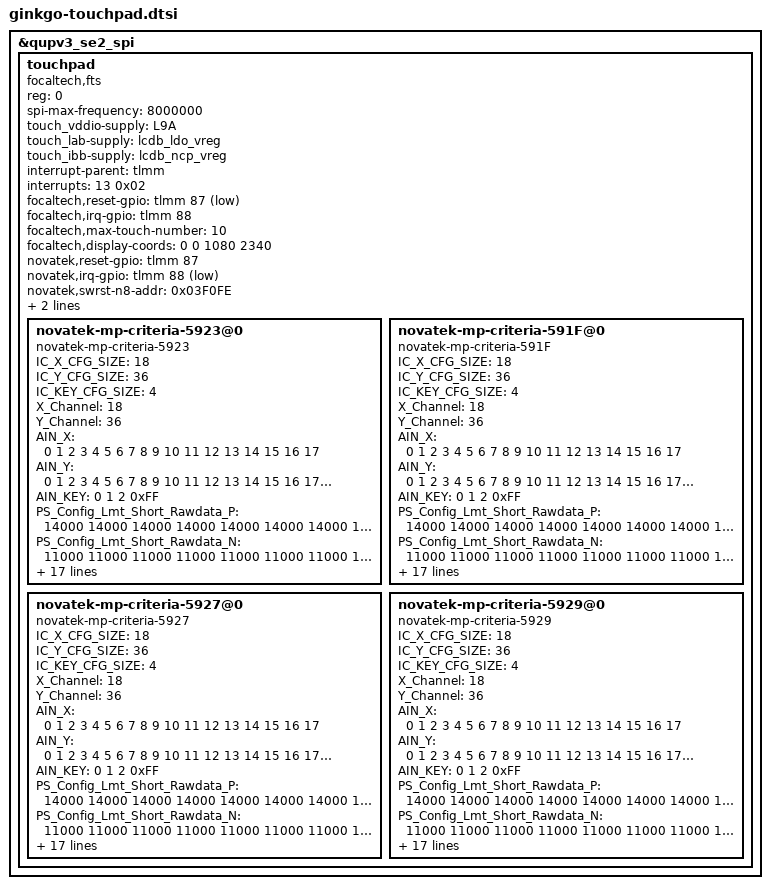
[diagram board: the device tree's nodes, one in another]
/*
 * TouchPad Device Tree For Xiaomi C3J
 */

&qupv3_se2_spi {

	status = "ok";

	touchpad{
		status = "ok";
		compatible = "focaltech,fts","novatek,NVT-ts-spi";
		reg = <0>; //Same as CS ID

		/* SPI Configuration */
		//spi-cs-high;
		spi-max-frequency = <8000000>;	//4800000,5000000,8000000,9600000,15000000,19200000

		/* regulator Configuration */
		touch_vddio-supply = <&L9A>;
		touch_lab-supply = <&lcdb_ldo_vreg>;
		touch_ibb-supply = <&lcdb_ncp_vreg>;

		/*
		 * [IC Vendor]Focaltech [IC Name]FT8719 - device tree
		 ********************************************************************
		 */

		/* Focaltech GPIO Configuration */
		interrupt-parent = <&tlmm>;
		interrupts = <13 0x02>;
		focaltech,reset-gpio = <&tlmm 87 0x01>;
		focaltech,irq-gpio = <&tlmm 88 0x02>;
		focaltech,max-touch-number = <10>;
		focaltech,display-coords =  <0 0 1080 2340>;

		/* Pinctrl Configuration */
		//pinctrl-names = "pmx_ts_active","pmx_ts_suspend","pmx_ts_release";
		//pinctrl-0 = <&ts_int_active &ts_reset_active>;
		//pinctrl-1 = <&ts_int_suspend &ts_reset_suspend>;
		//pinctrl-2 = <&ts_release>;

		/* Touch Key Configuration */
		//focaltech,have-key;
		//focaltech,key-number = <3>;
		//focaltech,keys = <139 102 158>;
		//focaltech,key-x-coords = <200 600 800>;
		//focaltech,key-y-coords = <2000 2000 2000>;

		/*
		 * [IC Vendor]Novatek [IC Name]NT36672A - device tree
		 ********************************************************************
		 */

		/* Novatek GPIO Configuration */
		novatek,reset-gpio = <&tlmm 87 0x00>;
		novatek,irq-gpio = <&tlmm 88 0x2001>;

		/* 525 */
		//novatek,swrst-n8-addr = <0x01F01A>;

		/* 672A, 525B */
		novatek,swrst-n8-addr = <0x03F0FE>;
		novatek,spi-rd-fast-addr = <0x03F310>;

		/* MP */
		novatek,mp-support-dt;

		/* for Xiaomi C3J 672A EBBG 6.3" */
		novatek-mp-criteria-5923@0 {/*{{{*/
			#address-cells = <1>;
			#size-cells = <0>;
			compatible = "novatek-mp-criteria-5923";

			/* MP Config */
			IC_X_CFG_SIZE = <18>;
			IC_Y_CFG_SIZE = <36>;
			IC_KEY_CFG_SIZE = <4>;
			X_Channel = <18>;
			Y_Channel = <36>;
			AIN_X = <0 1 2 3 4 5 6 7 8 9 10 11 12 13 14 15 16 17>;
			AIN_Y = <0 1 2 3 4 5 6 7 8 9 10 11 12 13 14 15 16 17
						18 19 20 21 22 23 24 25 26 27 28 29 30 31 32 33 34 35>;
			AIN_KEY = <0 1 2 0xFF>;

			/* MP Criteria */
			PS_Config_Lmt_Short_Rawdata_P = <
				14000 14000 14000 14000 14000 14000 14000 14000 14000 14000 14000 14000 14000 14000 14000 14000 14000 14000  
				14000 14000 14000 14000 14000 14000 14000 14000 14000 14000 14000 14000 14000 14000 14000 14000 14000 14000
				14000 14000 14000 14000 14000 14000 14000 14000 14000 14000 14000 14000 14000 14000 14000 14000 14000 14000
				14000 14000 14000 14000 14000 14000 14000 14000 14000 14000 14000 14000 14000 14000 14000 14000 14000 14000
				14000 14000 14000 14000 14000 14000 14000 14000 14000 14000 14000 14000 14000 14000 14000 14000 14000 14000
				14000 14000 14000 14000 14000 14000 14000 14000 14000 14000 14000 14000 14000 14000 14000 14000 14000 14000
				14000 14000 14000 14000 14000 14000 14000 14000 14000 14000 14000 14000 14000 14000 14000 14000 14000 14000
				14000 14000 14000 14000 14000 14000 14000 14000 14000 14000 14000 14000 14000 14000 14000 14000 14000 14000
				14000 14000 14000 14000 14000 14000 14000 14000 14000 14000 14000 14000 14000 14000 14000 14000 14000 14000
				14000 14000 14000 14000 14000 14000 14000 14000 14000 14000 14000 14000 14000 14000 14000 14000 14000 14000
				14000 14000 14000 14000 14000 14000 14000 14000 14000 14000 14000 14000 14000 14000 14000 14000 14000 14000
				14000 14000 14000 14000 14000 14000 14000 14000 14000 14000 14000 14000 14000 14000 14000 14000 14000 14000
				14000 14000 14000 14000 14000 14000 14000 14000 14000 14000 14000 14000 14000 14000 14000 14000 14000 14000
				14000 14000 14000 14000 14000 14000 14000 14000 14000 14000 14000 14000 14000 14000 14000 14000 14000 14000
				14000 14000 14000 14000 14000 14000 14000 14000 14000 14000 14000 14000 14000 14000 14000 14000 14000 14000
				14000 14000 14000 14000 14000 14000 14000 14000 14000 14000 14000 14000 14000 14000 14000 14000 14000 14000
				14000 14000 14000 14000 14000 14000 14000 14000 14000 14000 14000 14000 14000 14000 14000 14000 14000 14000
				14000 14000 14000 14000 14000 14000 14000 14000 14000 14000 14000 14000 14000 14000 14000 14000 14000 14000
				14000 14000 14000 14000 14000 14000 14000 14000 14000 14000 14000 14000 14000 14000 14000 14000 14000 14000
				14000 14000 14000 14000 14000 14000 14000 14000 14000 14000 14000 14000 14000 14000 14000 14000 14000 14000
				14000 14000 14000 14000 14000 14000 14000 14000 14000 14000 14000 14000 14000 14000 14000 14000 14000 14000
				14000 14000 14000 14000 14000 14000 14000 14000 14000 14000 14000 14000 14000 14000 14000 14000 14000 14000
				14000 14000 14000 14000 14000 14000 14000 14000 14000 14000 14000 14000 14000 14000 14000 14000 14000 14000
				14000 14000 14000 14000 14000 14000 14000 14000 14000 14000 14000 14000 14000 14000 14000 14000 14000 14000
				14000 14000 14000 14000 14000 14000 14000 14000 14000 14000 14000 14000 14000 14000 14000 14000 14000 14000
				14000 14000 14000 14000 14000 14000 14000 14000 14000 14000 14000 14000 14000 14000 14000 14000 14000 14000
				14000 14000 14000 14000 14000 14000 14000 14000 14000 14000 14000 14000 14000 14000 14000 14000 14000 14000
				14000 14000 14000 14000 14000 14000 14000 14000 14000 14000 14000 14000 14000 14000 14000 14000 14000 14000
				14000 14000 14000 14000 14000 14000 14000 14000 14000 14000 14000 14000 14000 14000 14000 14000 14000 14000
				14000 14000 14000 14000 14000 14000 14000 14000 14000 14000 14000 14000 14000 14000 14000 14000 14000 14000
				14000 14000 14000 14000 14000 14000 14000 14000 14000 14000 14000 14000 14000 14000 14000 14000 14000 14000
				14000 14000 14000 14000 14000 14000 14000 14000 14000 14000 14000 14000 14000 14000 14000 14000 14000 14000
				14000 14000 14000 14000 14000 14000 14000 14000 14000 14000 14000 14000 14000 14000 14000 14000 14000 14000
				14000 14000 14000 14000 14000 14000 14000 14000 14000 14000 14000 14000 14000 14000 14000 14000 14000 14000
				14000 14000 14000 14000 14000 14000 14000 14000 14000 14000 14000 14000 14000 14000 14000 14000 14000 14000
				14000 14000 14000 14000 14000 14000 14000 14000 14000 14000 14000 14000 14000 14000 14000 14000 14000 14000
				14000 14000 14000>;

			PS_Config_Lmt_Short_Rawdata_N = <
				11000 11000 11000 11000 11000 11000 11000 11000 11000 11000 11000 11000 11000 11000 11000 11000 11000 11000
				11000 11000 11000 11000 11000 11000 11000 11000 11000 11000 11000 11000 11000 11000 11000 11000 11000 11000
				11000 11000 11000 11000 11000 11000 11000 11000 11000 11000 11000 11000 11000 11000 11000 11000 11000 11000
				11000 11000 11000 11000 11000 11000 11000 11000 11000 11000 11000 11000 11000 11000 11000 11000 11000 11000
				11000 11000 11000 11000 11000 11000 11000 11000 11000 11000 11000 11000 11000 11000 11000 11000 11000 11000
				11000 11000 11000 11000 11000 11000 11000 11000 11000 11000 11000 11000 11000 11000 11000 11000 11000 11000
				11000 11000 11000 11000 11000 11000 11000 11000 11000 11000 11000 11000 11000 11000 11000 11000 11000 11000
				11000 11000 11000 11000 11000 11000 11000 11000 11000 11000 11000 11000 11000 11000 11000 11000 11000 11000
				11000 11000 11000 11000 11000 11000 11000 11000 11000 11000 11000 11000 11000 11000 11000 11000 11000 11000
				11000 11000 11000 11000 11000 11000 11000 11000 11000 11000 11000 11000 11000 11000 11000 11000 11000 11000
				11000 11000 11000 11000 11000 11000 11000 11000 11000 11000 11000 11000 11000 11000 11000 11000 11000 11000
				11000 11000 11000 11000 11000 11000 11000 11000 11000 11000 11000 11000 11000 11000 11000 11000 11000 11000
				11000 11000 11000 11000 11000 11000 11000 11000 11000 11000 11000 11000 11000 11000 11000 11000 11000 11000
				11000 11000 11000 11000 11000 11000 11000 11000 11000 11000 11000 11000 11000 11000 11000 11000 11000 11000
				11000 11000 11000 11000 11000 11000 11000 11000 11000 11000 11000 11000 11000 11000 11000 11000 11000 11000
				11000 11000 11000 11000 11000 11000 11000 11000 11000 11000 11000 11000 11000 11000 11000 11000 11000 11000
				11000 11000 11000 11000 11000 11000 11000 11000 11000 11000 11000 11000 11000 11000 11000 11000 11000 11000
				11000 11000 11000 11000 11000 11000 11000 11000 11000 11000 11000 11000 11000 11000 11000 11000 11000 11000
				11000 11000 11000 11000 11000 11000 11000 11000 11000 11000 11000 11000 11000 11000 11000 11000 11000 11000
				11000 11000 11000 11000 11000 11000 11000 11000 11000 11000 11000 11000 11000 11000 11000 11000 11000 11000
				11000 11000 11000 11000 11000 11000 11000 11000 11000 11000 11000 11000 11000 11000 11000 11000 11000 11000
				11000 11000 11000 11000 11000 11000 11000 11000 11000 11000 11000 11000 11000 11000 11000 11000 11000 11000
				11000 11000 11000 11000 11000 11000 11000 11000 11000 11000 11000 11000 11000 11000 11000 11000 11000 11000
				11000 11000 11000 11000 11000 11000 11000 11000 11000 11000 11000 11000 11000 11000 11000 11000 11000 11000
				11000 11000 11000 11000 11000 11000 11000 11000 11000 11000 11000 11000 11000 11000 11000 11000 11000 11000
				11000 11000 11000 11000 11000 11000 11000 11000 11000 11000 11000 11000 11000 11000 11000 11000 11000 11000
				11000 11000 11000 11000 11000 11000 11000 11000 11000 11000 11000 11000 11000 11000 11000 11000 11000 11000
				11000 11000 11000 11000 11000 11000 11000 11000 11000 11000 11000 11000 11000 11000 11000 11000 11000 11000
				11000 11000 11000 11000 11000 11000 11000 11000 11000 11000 11000 11000 11000 11000 11000 11000 11000 11000
				11000 11000 11000 11000 11000 11000 11000 11000 11000 11000 11000 11000 11000 11000 11000 11000 11000 11000
				11000 11000 11000 11000 11000 11000 11000 11000 11000 11000 11000 11000 11000 11000 11000 11000 11000 11000
				11000 11000 11000 11000 11000 11000 11000 11000 11000 11000 11000 11000 11000 11000 11000 11000 11000 11000
				11000 11000 11000 11000 11000 11000 11000 11000 11000 11000 11000 11000 11000 11000 11000 11000 11000 11000
				11000 11000 11000 11000 11000 11000 11000 11000 11000 11000 11000 11000 11000 11000 11000 11000 11000 11000
				11000 11000 11000 11000 11000 11000 11000 11000 11000 11000 11000 11000 11000 11000 11000 11000 11000 11000
				11000 11000 11000 11000 11000 11000 11000 11000 11000 11000 11000 11000 11000 11000 11000 11000 11000 11000
				11000 11000 11000>;

			PS_Config_Lmt_Open_Rawdata_P = <
			    65535 3376 3371 3377 3383 3366 3368 3312 65535 65535 3377 3436 3440 3450 3449 3429 3432 65535
			    3060 3095 3101 3102 3106 3093 3098 3085 2920 2968 3137 3150 3149 3159 3160 3151 3146 3098 
			    3205 3175 3179 3180 3184 3172 3173 3158 3159 3214 3210 3224 3225 3236 3237 3224 3220 3234 
			    3137 3107 3111 3111 3115 3103 3106 3090 3091 3140 3137 3150 3151 3160 3163 3156 3151 3168 
			    3211 3181 3188 3188 3189 3177 3181 3164 3164 3220 3215 3229 3232 3241 3244 3237 3233 3249 
			    3143 3114 3119 3116 3119 3108 3111 3094 3097 3141 3136 3150 3153 3160 3163 3159 3156 3175 
			    3215 3185 3190 3189 3193 3181 3182 3166 3169 3218 3210 3228 3229 3238 3241 3237 3232 3249 
			    3140 3111 3116 3114 3117 3107 3108 3091 3097 3138 3132 3147 3149 3156 3160 3160 3155 3175 
			    3212 3182 3189 3185 3190 3179 3180 3162 3168 3215 3207 3224 3224 3233 3237 3237 3232 3253 
			    3136 3106 3111 3108 3112 3102 3103 3088 3091 3140 3132 3149 3149 3156 3159 3162 3158 3180 
			    3212 3181 3189 3185 3188 3177 3179 3164 3168 3212 3203 3216 3219 3228 3229 3233 3228 3249 
			    3132 3101 3107 3103 3106 3094 3097 3084 3088 3130 3120 3132 3133 3141 3143 3149 3145 3168 
			    3202 3172 3180 3175 3179 3167 3169 3155 3159 3201 3190 3201 3202 3211 3214 3221 3220 3242 
			    3125 3095 3102 3098 3102 3091 3093 3082 3082 3123 3115 3123 3123 3133 3134 3143 3142 3166 
			    3193 3162 3172 3167 3169 3159 3163 3155 3151 3193 3185 3194 3193 3203 3205 3214 3210 3236 
			    3111 3081 3091 3085 3089 3078 3085 3075 3072 3106 3099 3107 3106 3115 3117 3125 3124 3150 
			    3176 3146 3156 3151 3154 3143 3149 3145 3137 3182 3177 3180 3180 3189 3190 3199 3199 3227 
			    3094 3065 3076 3071 3072 3062 3068 3060 3056 3098 3089 3097 3094 3104 3106 3115 3116 3140 
			    3160 3130 3140 3134 3138 3127 3133 3125 3123 3162 3154 3162 3158 3168 3171 3180 3181 3206 
			    3080 3049 3059 3054 3058 3046 3054 3045 3047 3081 3073 3081 3076 3085 3088 3097 3095 3124 
			    3141 3110 3120 3115 3119 3108 3115 3106 3108 3151 3143 3151 3146 3156 3159 3167 3167 3197 
			    3059 3025 3034 3032 3034 3024 3033 3023 3024 3060 3051 3060 3055 3064 3067 3073 3076 3104 
			    3119 3086 3094 3091 3094 3085 3091 3082 3084 3127 3119 3127 3121 3132 3134 3141 3143 3172 
			    3034 3002 3010 3006 3010 3000 3008 2999 3000 3034 3026 3036 3029 3038 3039 3047 3050 3078 
			    2899 2870 2881 2880 2881 2870 2878 2869 2876 2911 2899 2907 2902 2911 2915 2920 2924 2948 
			    2817 2789 2798 2795 2798 2789 2796 2787 2792 2824 2812 2821 2816 2824 2826 2833 2837 2861 
			    2878 2846 2855 2852 2855 2846 2854 2847 2851 2889 2881 2887 2882 2890 2893 2899 2903 2932 
			    2794 2761 2770 2766 2769 2763 2769 2763 2765 2787 2783 2794 2790 2796 2798 2804 2807 2835 
			    2851 2821 2829 2825 2828 2821 2829 2818 2824 2851 2846 2857 2852 2859 2860 2868 2870 2898 
			    2764 2734 2742 2738 2740 2733 2742 2730 2735 2760 2755 2766 2760 2766 2768 2776 2777 2802 
			    2816 2786 2792 2789 2791 2783 2792 2781 2787 2821 2816 2828 2821 2828 2829 2835 2838 2863 
			    2731 2701 2708 2704 2707 2700 2709 2698 2703 2726 2722 2735 2727 2734 2735 2743 2743 2769 
			    2783 2755 2761 2757 2760 2752 2764 2750 2756 2785 2779 2792 2783 2791 2792 2799 2800 2828 
			    2340 2668 2674 2670 2674 2665 2678 2662 2670 2692 2687 2703 2692 2699 2700 2708 2708 2371 
			    2310 2712 2718 2714 2718 2709 2724 2705 2714 2753 2748 2765 2753 2761 2761 2768 2769 2357 
			    2158 2565 2677 2686 2686 2666 2679 2662 2673 2701 2694 2711 2699 2720 2724 2717 2610 2193 
			    4096 4096 4096>;

			PS_Config_Lmt_Open_Rawdata_N = <
			    (-65535) 1818 1815 1819 1821 1812 1814 1784 (-65535) (-65535) 1819 1850 1852 1858 1857 1847 1848 (-65535)
			    1648 1667 1670 1670 1672 1665 1668 1661 1572 1598 1689 1696 1695 1701 1702 1697 1694 1668        
			    1726 1709 1712 1712 1714 1708 1709 1700 1701 1730 1728 1736 1737 1742 1743 1736 1734 1742        
			    1689 1673 1675 1675 1677 1671 1672 1664 1665 1691 1689 1696 1697 1702 1703 1700 1697 1706        
			    1729 1713 1716 1716 1717 1711 1713 1704 1704 1734 1731 1739 1740 1745 1747 1743 1741 1749        
			    1693 1677 1679 1678 1679 1674 1675 1666 1667 1691 1688 1696 1698 1702 1703 1701 1700 1709        
			    1731 1715 1718 1717 1719 1713 1714 1705 1707 1733 1728 1738 1739 1744 1745 1743 1740 1749        
			    1691 1675 1678 1677 1679 1673 1674 1665 1667 1690 1686 1695 1695 1700 1702 1702 1699 1709        
			    1730 1714 1717 1715 1718 1712 1712 1702 1706 1731 1727 1736 1736 1741 1743 1743 1740 1751        
			    1688 1672 1675 1674 1676 1670 1671 1663 1665 1691 1686 1695 1695 1700 1701 1702 1700 1712        
			    1730 1713 1717 1715 1716 1711 1712 1704 1706 1730 1725 1732 1733 1738 1739 1741 1738 1749        
			    1686 1670 1673 1671 1672 1666 1667 1660 1663 1686 1680 1686 1687 1691 1693 1695 1693 1706        
			    1724 1708 1712 1709 1712 1705 1707 1699 1701 1723 1718 1723 1724 1729 1730 1735 1734 1746        
			    1683 1667 1670 1668 1670 1665 1665 1660 1660 1681 1677 1681 1681 1687 1688 1693 1692 1705        
			    1719 1702 1708 1705 1707 1701 1703 1699 1697 1719 1715 1720 1719 1725 1726 1730 1728 1742        
			    1675 1659 1665 1661 1663 1658 1661 1656 1654 1672 1669 1673 1672 1677 1679 1683 1682 1696        
			    1710 1694 1700 1697 1698 1693 1695 1693 1689 1714 1711 1712 1712 1717 1718 1723 1723 1737        
			    1666 1651 1656 1653 1654 1649 1652 1648 1646 1668 1663 1667 1666 1672 1672 1677 1678 1691        
			    1702 1686 1691 1688 1690 1684 1687 1683 1681 1702 1698 1702 1700 1706 1707 1712 1713 1726        
			    1658 1642 1647 1644 1646 1640 1644 1639 1641 1659 1655 1659 1656 1661 1663 1667 1667 1682        
			    1691 1674 1680 1677 1679 1674 1677 1672 1674 1697 1693 1697 1694 1700 1701 1705 1705 1721        
			    1647 1629 1634 1632 1634 1628 1633 1628 1628 1648 1643 1648 1645 1650 1651 1655 1656 1672        
			    1679 1662 1666 1665 1666 1661 1665 1660 1660 1684 1679 1684 1681 1686 1688 1691 1693 1708        
			    1634 1616 1621 1618 1621 1616 1620 1615 1616 1634 1630 1635 1631 1636 1637 1641 1642 1658        
			    1561 1546 1551 1551 1551 1546 1550 1545 1548 1567 1561 1565 1562 1567 1569 1572 1574 1588        
			    1517 1502 1506 1505 1506 1502 1506 1501 1504 1520 1514 1519 1516 1520 1522 1525 1527 1541        
			    1550 1532 1537 1536 1537 1532 1537 1533 1535 1555 1551 1555 1552 1556 1558 1561 1563 1579        
			    1504 1487 1492 1490 1491 1488 1491 1488 1489 1501 1499 1504 1502 1506 1506 1510 1511 1527        
			    1535 1519 1523 1521 1523 1519 1523 1518 1520 1535 1532 1539 1536 1539 1540 1544 1546 1560        
			    1488 1472 1476 1474 1476 1471 1476 1470 1473 1486 1483 1490 1486 1490 1490 1495 1495 1509        
			    1516 1500 1504 1502 1503 1499 1504 1497 1501 1519 1516 1523 1519 1523 1523 1527 1528 1541        
			    1471 1455 1458 1456 1457 1454 1459 1453 1455 1468 1466 1473 1469 1472 1473 1477 1477 1491        
			    1499 1483 1487 1485 1486 1482 1488 1481 1484 1499 1497 1504 1499 1503 1504 1507 1508 1523        
			    1260 1436 1440 1438 1440 1435 1442 1434 1438 1450 1447 1455 1450 1453 1454 1458 1458 1277        
			    1244 1460 1464 1462 1464 1459 1467 1457 1462 1483 1480 1489 1483 1487 1487 1490 1491 1269        
			    1162 1381 1441 1446 1446 1436 1443 1434 1439 1455 1450 1460 1453 1464 1467 1463 1406 1181        
				50 50 50>;

			PS_Config_Lmt_FW_Rawdata_P = <
			    65535 2160 2160 2160 2160 2160 2160 2160 65535 65535 2160 2160 2160 2160 2160 2160 2160 65535
			    2160 2160 2160 2160 2160 2160 2160 2160 2160 2160 2160 2160 2160 2160 2160 2160 2160 2160 
			    2160 2160 2160 2160 2160 2160 2160 2160 2160 2160 2160 2160 2160 2160 2160 2160 2160 2160 
			    2160 2160 2160 2160 2160 2160 2160 2160 2160 2160 2160 2160 2160 2160 2160 2160 2160 2160 
			    2160 2160 2160 2160 2160 2160 2160 2160 2160 2160 2160 2160 2160 2160 2160 2160 2160 2160 
			    2160 2160 2160 2160 2160 2160 2160 2160 2160 2160 2160 2160 2160 2160 2160 2160 2160 2160 
			    2160 2160 2160 2160 2160 2160 2160 2160 2160 2160 2160 2160 2160 2160 2160 2160 2160 2160 
			    2160 2160 2160 2160 2160 2160 2160 2160 2160 2160 2160 2160 2160 2160 2160 2160 2160 2160 
			    2160 2160 2160 2160 2160 2160 2160 2160 2160 2160 2160 2160 2160 2160 2160 2160 2160 2160 
			    2160 2160 2160 2160 2160 2160 2160 2160 2160 2160 2160 2160 2160 2160 2160 2160 2160 2160 
			    2160 2160 2160 2160 2160 2160 2160 2160 2160 2160 2160 2160 2160 2160 2160 2160 2160 2160 
			    2160 2160 2160 2160 2160 2160 2160 2160 2160 2160 2160 2160 2160 2160 2160 2160 2160 2160 
			    2160 2160 2160 2160 2160 2160 2160 2160 2160 2160 2160 2160 2160 2160 2160 2160 2160 2160 
			    2160 2160 2160 2160 2160 2160 2160 2160 2160 2160 2160 2160 2160 2160 2160 2160 2160 2160 
			    2160 2160 2160 2160 2160 2160 2160 2160 2160 2160 2160 2160 2160 2160 2160 2160 2160 2160 
			    2160 2160 2160 2160 2160 2160 2160 2160 2160 2160 2160 2160 2160 2160 2160 2160 2160 2160 
			    2160 2160 2160 2160 2160 2160 2160 2160 2160 2160 2160 2160 2160 2160 2160 2160 2160 2160 
			    2160 2160 2160 2160 2160 2160 2160 2160 2160 2160 2160 2160 2160 2160 2160 2160 2160 2160 
			    2160 2160 2160 2160 2160 2160 2160 2160 2160 2160 2160 2160 2160 2160 2160 2160 2160 2160 
			    2160 2160 2160 2160 2160 2160 2160 2160 2160 2160 2160 2160 2160 2160 2160 2160 2160 2160 
			    2160 2160 2160 2160 2160 2160 2160 2160 2160 2160 2160 2160 2160 2160 2160 2160 2160 2160 
			    2160 2160 2160 2160 2160 2160 2160 2160 2160 2160 2160 2160 2160 2160 2160 2160 2160 2160 
			    2160 2160 2160 2160 2160 2160 2160 2160 2160 2160 2160 2160 2160 2160 2160 2160 2160 2160 
			    2160 2160 2160 2160 2160 2160 2160 2160 2160 2160 2160 2160 2160 2160 2160 2160 2160 2160 
			    2160 2160 2160 2160 2160 2160 2160 2160 2160 2160 2160 2160 2160 2160 2160 2160 2160 2160 
			    2160 2160 2160 2160 2160 2160 2160 2160 2160 2160 2160 2160 2160 2160 2160 2160 2160 2160 
			    2160 2160 2160 2160 2160 2160 2160 2160 2160 2160 2160 2160 2160 2160 2160 2160 2160 2160 
			    2160 2160 2160 2160 2160 2160 2160 2160 2160 2160 2160 2160 2160 2160 2160 2160 2160 2160 
			    2160 2160 2160 2160 2160 2160 2160 2160 2160 2160 2160 2160 2160 2160 2160 2160 2160 2160 
			    2160 2160 2160 2160 2160 2160 2160 2160 2160 2160 2160 2160 2160 2160 2160 2160 2160 2160 
			    2160 2160 2160 2160 2160 2160 2160 2160 2160 2160 2160 2160 2160 2160 2160 2160 2160 2160 
			    2160 2160 2160 2160 2160 2160 2160 2160 2160 2160 2160 2160 2160 2160 2160 2160 2160 2160 
			    2160 2160 2160 2160 2160 2160 2160 2160 2160 2160 2160 2160 2160 2160 2160 2160 2160 2160 
			    2160 2160 2160 2160 2160 2160 2160 2160 2160 2160 2160 2160 2160 2160 2160 2160 2160 2160 
			    2160 2160 2160 2160 2160 2160 2160 2160 2160 2160 2160 2160 2160 2160 2160 2160 2160 2160 
			    2160 2160 2160 2160 2160 2160 2160 2160 2160 2160 2160 2160 2160 2160 2160 2160 2160 2160 
				1920 1920 1920>;

			PS_Config_Lmt_FW_Rawdata_N = <
			    (-65535) 1040 1040 1040 1040 1040 1040 1040 (-65535) (-65535) 1040 1040 1040 1040 1040 1040 1040 (-65535)
			    1040 1040 1040 1040 1040 1040 1040 1040 1040 1040 1040 1040 1040 1040 1040 1040 1040 1040        
			    1040 1040 1040 1040 1040 1040 1040 1040 1040 1040 1040 1040 1040 1040 1040 1040 1040 1040        
			    1040 1040 1040 1040 1040 1040 1040 1040 1040 1040 1040 1040 1040 1040 1040 1040 1040 1040        
			    1040 1040 1040 1040 1040 1040 1040 1040 1040 1040 1040 1040 1040 1040 1040 1040 1040 1040        
			    1040 1040 1040 1040 1040 1040 1040 1040 1040 1040 1040 1040 1040 1040 1040 1040 1040 1040        
			    1040 1040 1040 1040 1040 1040 1040 1040 1040 1040 1040 1040 1040 1040 1040 1040 1040 1040        
			    1040 1040 1040 1040 1040 1040 1040 1040 1040 1040 1040 1040 1040 1040 1040 1040 1040 1040        
			    1040 1040 1040 1040 1040 1040 1040 1040 1040 1040 1040 1040 1040 1040 1040 1040 1040 1040        
			    1040 1040 1040 1040 1040 1040 1040 1040 1040 1040 1040 1040 1040 1040 1040 1040 1040 1040        
			    1040 1040 1040 1040 1040 1040 1040 1040 1040 1040 1040 1040 1040 1040 1040 1040 1040 1040        
			    1040 1040 1040 1040 1040 1040 1040 1040 1040 1040 1040 1040 1040 1040 1040 1040 1040 1040        
			    1040 1040 1040 1040 1040 1040 1040 1040 1040 1040 1040 1040 1040 1040 1040 1040 1040 1040        
			    1040 1040 1040 1040 1040 1040 1040 1040 1040 1040 1040 1040 1040 1040 1040 1040 1040 1040        
			    1040 1040 1040 1040 1040 1040 1040 1040 1040 1040 1040 1040 1040 1040 1040 1040 1040 1040        
			    1040 1040 1040 1040 1040 1040 1040 1040 1040 1040 1040 1040 1040 1040 1040 1040 1040 1040        
			    1040 1040 1040 1040 1040 1040 1040 1040 1040 1040 1040 1040 1040 1040 1040 1040 1040 1040        
			    1040 1040 1040 1040 1040 1040 1040 1040 1040 1040 1040 1040 1040 1040 1040 1040 1040 1040        
			    1040 1040 1040 1040 1040 1040 1040 1040 1040 1040 1040 1040 1040 1040 1040 1040 1040 1040        
			    1040 1040 1040 1040 1040 1040 1040 1040 1040 1040 1040 1040 1040 1040 1040 1040 1040 1040        
			    1040 1040 1040 1040 1040 1040 1040 1040 1040 1040 1040 1040 1040 1040 1040 1040 1040 1040        
			    1040 1040 1040 1040 1040 1040 1040 1040 1040 1040 1040 1040 1040 1040 1040 1040 1040 1040        
			    1040 1040 1040 1040 1040 1040 1040 1040 1040 1040 1040 1040 1040 1040 1040 1040 1040 1040        
			    1040 1040 1040 1040 1040 1040 1040 1040 1040 1040 1040 1040 1040 1040 1040 1040 1040 1040        
			    1040 1040 1040 1040 1040 1040 1040 1040 1040 1040 1040 1040 1040 1040 1040 1040 1040 1040        
			    1040 1040 1040 1040 1040 1040 1040 1040 1040 1040 1040 1040 1040 1040 1040 1040 1040 1040        
			    1040 1040 1040 1040 1040 1040 1040 1040 1040 1040 1040 1040 1040 1040 1040 1040 1040 1040        
			    1040 1040 1040 1040 1040 1040 1040 1040 1040 1040 1040 1040 1040 1040 1040 1040 1040 1040        
			    1040 1040 1040 1040 1040 1040 1040 1040 1040 1040 1040 1040 1040 1040 1040 1040 1040 1040        
			    1040 1040 1040 1040 1040 1040 1040 1040 1040 1040 1040 1040 1040 1040 1040 1040 1040 1040        
			    1040 1040 1040 1040 1040 1040 1040 1040 1040 1040 1040 1040 1040 1040 1040 1040 1040 1040        
			    1040 1040 1040 1040 1040 1040 1040 1040 1040 1040 1040 1040 1040 1040 1040 1040 1040 1040        
			    1040 1040 1040 1040 1040 1040 1040 1040 1040 1040 1040 1040 1040 1040 1040 1040 1040 1040        
			    1040 1040 1040 1040 1040 1040 1040 1040 1040 1040 1040 1040 1040 1040 1040 1040 1040 1040        
			    1040 1040 1040 1040 1040 1040 1040 1040 1040 1040 1040 1040 1040 1040 1040 1040 1040 1040        
			    1040 1040 1040 1040 1040 1040 1040 1040 1040 1040 1040 1040 1040 1040 1040 1040 1040 1040        
				240 240 240>;

			PS_Config_Lmt_FW_CC_P = <
			    65535 129 127 126 127 127 126 130 65535 65535 134 130 131 131 130 130 133 65535
			    121 118 116 116 116 117 116 117 117 118 118 117 117 117 117 117 118 121        
			    120 116 116 116 116 116 114 116 116 121 121 120 120 120 120 120 121 124        
			    120 117 116 116 116 116 116 116 117 120 118 118 118 117 117 118 118 121        
			    120 116 116 116 116 116 116 116 116 121 120 118 118 118 118 118 120 122        
			    121 118 117 117 117 117 117 118 118 118 118 117 117 117 117 117 118 121        
			    118 116 116 116 114 116 116 116 116 122 121 120 121 120 120 120 121 124        
			    120 116 116 116 116 116 116 117 117 120 118 117 118 117 117 117 118 121        
			    118 116 116 116 116 116 116 116 116 121 120 118 118 118 118 118 118 122        
			    121 117 117 117 117 117 117 118 118 121 118 117 117 117 117 117 117 121        
			    118 116 114 114 114 116 116 116 116 124 121 120 120 118 118 118 120 122        
			    118 116 116 116 116 116 116 117 117 122 118 117 118 117 117 117 117 120        
			    118 116 116 116 116 116 116 117 116 124 121 118 118 118 117 117 118 121        
			    120 117 116 117 117 118 117 120 118 122 120 116 117 116 116 116 116 118        
			    117 114 114 114 114 116 116 118 116 126 121 120 120 118 118 118 118 121        
			    118 116 116 116 116 116 116 120 117 124 121 117 117 116 116 116 116 118        
			    118 116 116 116 116 116 116 118 117 125 121 118 118 117 117 117 117 120        
			    118 116 117 117 117 118 117 118 118 122 118 116 116 116 116 116 116 118        
			    117 114 114 114 114 116 116 117 116 126 121 118 118 118 118 118 118 121        
			    118 116 116 116 116 116 116 118 120 124 118 117 117 116 116 116 116 118        
			    118 116 116 116 116 116 116 117 117 125 118 118 118 117 117 117 117 118        
			    118 116 117 117 117 118 118 118 118 122 117 116 116 116 116 116 114 117        
			    117 114 114 116 116 116 116 117 116 126 120 118 118 118 118 117 117 120        
			    118 116 116 116 116 117 117 118 117 124 117 116 117 116 116 116 116 117        
			    116 114 114 114 114 116 116 117 116 122 118 116 116 114 114 114 114 117        
			    118 116 116 116 116 118 117 118 117 121 117 116 116 113 113 113 113 116        
			    116 113 113 114 114 116 116 117 116 120 120 118 118 116 116 116 116 118        
			    117 116 116 116 116 116 116 118 116 116 118 116 116 114 114 114 113 116        
			    117 114 114 116 116 116 116 118 116 116 118 116 117 116 116 116 116 117        
			    118 116 116 116 116 118 117 118 117 114 116 114 114 113 113 113 113 116        
			    116 114 113 114 114 116 114 117 114 117 120 117 117 116 116 116 116 118        
			    117 114 116 116 116 116 116 118 116 114 117 114 116 113 113 113 113 116        
			    116 114 114 114 116 116 116 118 116 116 118 116 116 114 114 114 114 116        
			    116 116 116 116 116 117 118 120 116 113 117 114 113 113 113 113 112 112        
			    113 113 113 113 113 116 116 117 114 116 120 118 116 116 116 116 116 114        
			    122 125 126 126 125 126 127 129 129 129 129 126 125 124 124 124 124 121        
				314 314 314>;

			PS_Config_Lmt_FW_CC_N = <
			    (-65535) 69 69 68 69 69 68 70 (-65535) (-65535) 72 70 71 71 70 70 71 (-65535)
			    65 64 62 62 62 63 62 63 63 64 64 63 63 63 63 63 64 65                
			    64 62 62 62 62 62 62 62 62 65 65 64 64 64 64 64 65 67                
			    64 63 62 62 62 62 62 62 63 64 64 64 64 63 63 64 64 65                
			    64 62 62 62 62 62 62 62 62 65 64 64 64 64 64 64 64 66                
			    65 64 63 63 63 63 63 64 64 64 64 63 63 63 63 63 64 65                
			    64 62 62 62 62 62 62 62 62 66 65 64 65 64 64 64 65 67                
			    64 62 62 62 62 62 62 63 63 64 64 63 64 63 63 63 64 65                
			    64 62 62 62 62 62 62 62 62 65 64 64 64 64 64 64 64 66                
			    65 63 63 63 63 63 63 64 64 65 64 63 63 63 63 63 63 65                
			    64 62 62 62 62 62 62 62 62 67 65 64 64 64 64 64 64 66                
			    64 62 62 62 62 62 62 63 63 66 64 63 64 63 63 63 63 64                
			    64 62 62 62 62 62 62 63 62 67 65 64 64 64 63 63 64 65                
			    64 63 62 63 63 64 63 64 64 66 64 62 63 62 62 62 62 64                
			    63 62 62 62 62 62 62 64 62 68 65 64 64 64 64 64 64 65                
			    64 62 62 62 62 62 62 64 63 67 65 63 63 62 62 62 62 64                
			    64 62 62 62 62 62 62 64 63 67 65 64 64 63 63 63 63 64                
			    64 62 63 63 63 64 63 64 64 66 64 62 62 62 62 62 62 64                
			    63 62 62 62 62 62 62 63 62 68 65 64 64 64 64 64 64 65                
			    64 62 62 62 62 62 62 64 64 67 64 63 63 62 62 62 62 64                
			    64 62 62 62 62 62 62 63 63 67 64 64 64 63 63 63 63 64                
			    64 62 63 63 63 64 64 64 64 66 63 62 62 62 62 62 62 63                
			    63 62 62 62 62 62 62 63 62 68 64 64 64 64 64 63 63 64                
			    64 62 62 62 62 63 63 64 63 67 63 62 63 62 62 62 62 63                
			    62 62 62 62 62 62 62 63 62 66 64 62 62 62 62 62 62 63                
			    64 62 62 62 62 64 63 64 63 65 63 62 62 61 61 61 61 62                
			    62 61 61 62 62 62 62 63 62 64 64 64 64 62 62 62 62 64                
			    63 62 62 62 62 62 62 64 62 62 64 62 62 62 62 62 61 62                
			    63 62 62 62 62 62 62 64 62 62 64 62 63 62 62 62 62 63                
			    64 62 62 62 62 64 63 64 63 62 62 62 62 61 61 61 61 62                
			    62 62 61 62 62 62 62 63 62 63 64 63 63 62 62 62 62 64                
			    63 62 62 62 62 62 62 64 62 62 63 62 62 61 61 61 61 62                
			    62 62 62 62 62 62 62 64 62 62 64 62 62 62 62 62 62 62                
			    62 62 62 62 62 63 64 64 62 61 63 62 61 61 61 61 60 60                
			    61 61 61 61 61 62 62 63 62 62 64 64 62 62 62 62 62 62                
			    66 67 68 68 67 68 69 69 69 69 69 68 67 67 67 67 67 65                
				30 30 30>;

			PS_Config_Lmt_FW_Diff_P = <
			    65535 50 50 50 50 50 50 50 65535 65535 50 50 50 50 50 50 50 65535
			    50 50 50 50 50 50 50 50 50 50 50 50 50 50 50 50 50 50    
			    50 50 50 50 50 50 50 50 50 50 50 50 50 50 50 50 50 50    
			    50 50 50 50 50 50 50 50 50 50 50 50 50 50 50 50 50 50    
			    50 50 50 50 50 50 50 50 50 50 50 50 50 50 50 50 50 50    
			    50 50 50 50 50 50 50 50 50 50 50 50 50 50 50 50 50 50    
			    50 50 50 50 50 50 50 50 50 50 50 50 50 50 50 50 50 50    
			    50 50 50 50 50 50 50 50 50 50 50 50 50 50 50 50 50 50    
			    50 50 50 50 50 50 50 50 50 50 50 50 50 50 50 50 50 50    
			    50 50 50 50 50 50 50 50 50 50 50 50 50 50 50 50 50 50    
			    50 50 50 50 50 50 50 50 50 50 50 50 50 50 50 50 50 50    
			    50 50 50 50 50 50 50 50 50 50 50 50 50 50 50 50 50 50    
			    50 50 50 50 50 50 50 50 50 50 50 50 50 50 50 50 50 50    
			    50 50 50 50 50 50 50 50 50 50 50 50 50 50 50 50 50 50    
			    50 50 50 50 50 50 50 50 50 50 50 50 50 50 50 50 50 50    
			    50 50 50 50 50 50 50 50 50 50 50 50 50 50 50 50 50 50    
			    50 50 50 50 50 50 50 50 50 50 50 50 50 50 50 50 50 50    
			    50 50 50 50 50 50 50 50 50 50 50 50 50 50 50 50 50 50    
			    50 50 50 50 50 50 50 50 50 50 50 50 50 50 50 50 50 50    
			    50 50 50 50 50 50 50 50 50 50 50 50 50 50 50 50 50 50    
			    50 50 50 50 50 50 50 50 50 50 50 50 50 50 50 50 50 50    
			    50 50 50 50 50 50 50 50 50 50 50 50 50 50 50 50 50 50    
			    50 50 50 50 50 50 50 50 50 50 50 50 50 50 50 50 50 50    
			    50 50 50 50 50 50 50 50 50 50 50 50 50 50 50 50 50 50    
			    50 50 50 50 50 50 50 50 50 50 50 50 50 50 50 50 50 50    
			    50 50 50 50 50 50 50 50 50 50 50 50 50 50 50 50 50 50    
			    50 50 50 50 50 50 50 50 50 50 50 50 50 50 50 50 50 50    
			    50 50 50 50 50 50 50 50 50 50 50 50 50 50 50 50 50 50    
			    50 50 50 50 50 50 50 50 50 50 50 50 50 50 50 50 50 50    
			    50 50 50 50 50 50 50 50 50 50 50 50 50 50 50 50 50 50    
			    50 50 50 50 50 50 50 50 50 50 50 50 50 50 50 50 50 50    
			    50 50 50 50 50 50 50 50 50 50 50 50 50 50 50 50 50 50    
			    50 50 50 50 50 50 50 50 50 50 50 50 50 50 50 50 50 50    
			    50 50 50 50 50 50 50 50 50 50 50 50 50 50 50 50 50 50    
			    50 50 50 50 50 50 50 50 50 50 50 50 50 50 50 50 50 50    
			    50 50 50 50 50 50 50 50 50 50 50 50 50 50 50 50 50 50    
				75 75 75>;

			PS_Config_Lmt_FW_Diff_N = <
			    (-65535) (-50) (-50) (-50) (-50) (-50) (-50) (-50) (-65535) (-65535) (-50) (-50) (-50) (-50) (-50) (-50) (-50) (-65535)
			    (-50) (-50) (-50) (-50) (-50) (-50) (-50) (-50) (-50) (-50) (-50) (-50) (-50) (-50) (-50) (-50) (-50) (-50)        
			    (-50) (-50) (-50) (-50) (-50) (-50) (-50) (-50) (-50) (-50) (-50) (-50) (-50) (-50) (-50) (-50) (-50) (-50)        
			    (-50) (-50) (-50) (-50) (-50) (-50) (-50) (-50) (-50) (-50) (-50) (-50) (-50) (-50) (-50) (-50) (-50) (-50)        
			    (-50) (-50) (-50) (-50) (-50) (-50) (-50) (-50) (-50) (-50) (-50) (-50) (-50) (-50) (-50) (-50) (-50) (-50)        
			    (-50) (-50) (-50) (-50) (-50) (-50) (-50) (-50) (-50) (-50) (-50) (-50) (-50) (-50) (-50) (-50) (-50) (-50)        
			    (-50) (-50) (-50) (-50) (-50) (-50) (-50) (-50) (-50) (-50) (-50) (-50) (-50) (-50) (-50) (-50) (-50) (-50)        
			    (-50) (-50) (-50) (-50) (-50) (-50) (-50) (-50) (-50) (-50) (-50) (-50) (-50) (-50) (-50) (-50) (-50) (-50)        
			    (-50) (-50) (-50) (-50) (-50) (-50) (-50) (-50) (-50) (-50) (-50) (-50) (-50) (-50) (-50) (-50) (-50) (-50)        
			    (-50) (-50) (-50) (-50) (-50) (-50) (-50) (-50) (-50) (-50) (-50) (-50) (-50) (-50) (-50) (-50) (-50) (-50)        
			    (-50) (-50) (-50) (-50) (-50) (-50) (-50) (-50) (-50) (-50) (-50) (-50) (-50) (-50) (-50) (-50) (-50) (-50)        
			    (-50) (-50) (-50) (-50) (-50) (-50) (-50) (-50) (-50) (-50) (-50) (-50) (-50) (-50) (-50) (-50) (-50) (-50)        
			    (-50) (-50) (-50) (-50) (-50) (-50) (-50) (-50) (-50) (-50) (-50) (-50) (-50) (-50) (-50) (-50) (-50) (-50)        
			    (-50) (-50) (-50) (-50) (-50) (-50) (-50) (-50) (-50) (-50) (-50) (-50) (-50) (-50) (-50) (-50) (-50) (-50)        
			    (-50) (-50) (-50) (-50) (-50) (-50) (-50) (-50) (-50) (-50) (-50) (-50) (-50) (-50) (-50) (-50) (-50) (-50)        
			    (-50) (-50) (-50) (-50) (-50) (-50) (-50) (-50) (-50) (-50) (-50) (-50) (-50) (-50) (-50) (-50) (-50) (-50)        
			    (-50) (-50) (-50) (-50) (-50) (-50) (-50) (-50) (-50) (-50) (-50) (-50) (-50) (-50) (-50) (-50) (-50) (-50)        
			    (-50) (-50) (-50) (-50) (-50) (-50) (-50) (-50) (-50) (-50) (-50) (-50) (-50) (-50) (-50) (-50) (-50) (-50)        
			    (-50) (-50) (-50) (-50) (-50) (-50) (-50) (-50) (-50) (-50) (-50) (-50) (-50) (-50) (-50) (-50) (-50) (-50)        
			    (-50) (-50) (-50) (-50) (-50) (-50) (-50) (-50) (-50) (-50) (-50) (-50) (-50) (-50) (-50) (-50) (-50) (-50)        
			    (-50) (-50) (-50) (-50) (-50) (-50) (-50) (-50) (-50) (-50) (-50) (-50) (-50) (-50) (-50) (-50) (-50) (-50)        
			    (-50) (-50) (-50) (-50) (-50) (-50) (-50) (-50) (-50) (-50) (-50) (-50) (-50) (-50) (-50) (-50) (-50) (-50)        
			    (-50) (-50) (-50) (-50) (-50) (-50) (-50) (-50) (-50) (-50) (-50) (-50) (-50) (-50) (-50) (-50) (-50) (-50)        
			    (-50) (-50) (-50) (-50) (-50) (-50) (-50) (-50) (-50) (-50) (-50) (-50) (-50) (-50) (-50) (-50) (-50) (-50)        
			    (-50) (-50) (-50) (-50) (-50) (-50) (-50) (-50) (-50) (-50) (-50) (-50) (-50) (-50) (-50) (-50) (-50) (-50)        
			    (-50) (-50) (-50) (-50) (-50) (-50) (-50) (-50) (-50) (-50) (-50) (-50) (-50) (-50) (-50) (-50) (-50) (-50)        
			    (-50) (-50) (-50) (-50) (-50) (-50) (-50) (-50) (-50) (-50) (-50) (-50) (-50) (-50) (-50) (-50) (-50) (-50)        
			    (-50) (-50) (-50) (-50) (-50) (-50) (-50) (-50) (-50) (-50) (-50) (-50) (-50) (-50) (-50) (-50) (-50) (-50)        
			    (-50) (-50) (-50) (-50) (-50) (-50) (-50) (-50) (-50) (-50) (-50) (-50) (-50) (-50) (-50) (-50) (-50) (-50)        
			    (-50) (-50) (-50) (-50) (-50) (-50) (-50) (-50) (-50) (-50) (-50) (-50) (-50) (-50) (-50) (-50) (-50) (-50)        
			    (-50) (-50) (-50) (-50) (-50) (-50) (-50) (-50) (-50) (-50) (-50) (-50) (-50) (-50) (-50) (-50) (-50) (-50)        
			    (-50) (-50) (-50) (-50) (-50) (-50) (-50) (-50) (-50) (-50) (-50) (-50) (-50) (-50) (-50) (-50) (-50) (-50)        
			    (-50) (-50) (-50) (-50) (-50) (-50) (-50) (-50) (-50) (-50) (-50) (-50) (-50) (-50) (-50) (-50) (-50) (-50)        
			    (-50) (-50) (-50) (-50) (-50) (-50) (-50) (-50) (-50) (-50) (-50) (-50) (-50) (-50) (-50) (-50) (-50) (-50)        
			    (-50) (-50) (-50) (-50) (-50) (-50) (-50) (-50) (-50) (-50) (-50) (-50) (-50) (-50) (-50) (-50) (-50) (-50)        
			    (-50) (-50) (-50) (-50) (-50) (-50) (-50) (-50) (-50) (-50) (-50) (-50) (-50) (-50) (-50) (-50) (-50) (-50)        
				(-75) (-75) (-75)>;

			PS_Config_Diff_Test_Frame = <50>;
		};/*}}}*/

		/* for Xiaomi C3J 672A TM 6.3" */
		novatek-mp-criteria-591F@0 {/*{{{*/
			#address-cells = <1>;
			#size-cells = <0>;
			compatible = "novatek-mp-criteria-591F";

			/* MP Config */
			IC_X_CFG_SIZE = <18>;
			IC_Y_CFG_SIZE = <36>;
			IC_KEY_CFG_SIZE = <4>;
			X_Channel = <18>;
			Y_Channel = <36>;
			AIN_X = <0 1 2 3 4 5 6 7 8 9 10 11 12 13 14 15 16 17>;
			AIN_Y = <0 1 2 3 4 5 6 7 8 9 10 11 12 13 14 15 16 17
						18 19 20 21 22 23 24 25 26 27 28 29 30 31 32 33 34 35>;
			AIN_KEY = <0 1 2 0xFF>;

			/* MP Criteria */
			PS_Config_Lmt_Short_Rawdata_P = <
				14000	14000	14000	14000	14000	14000	14000	14000	14000	14000	14000	14000	14000	14000	14000	14000	14000	14000
				14000	14000	14000	14000	14000	14000	14000	14000	14000	14000	14000	14000	14000	14000	14000	14000	14000	14000
				14000	14000	14000	14000	14000	14000	14000	14000	14000	14000	14000	14000	14000	14000	14000	14000	14000	14000
				14000	14000	14000	14000	14000	14000	14000	14000	14000	14000	14000	14000	14000	14000	14000	14000	14000	14000
				14000	14000	14000	14000	14000	14000	14000	14000	14000	14000	14000	14000	14000	14000	14000	14000	14000	14000
				14000	14000	14000	14000	14000	14000	14000	14000	14000	14000	14000	14000	14000	14000	14000	14000	14000	14000
				14000	14000	14000	14000	14000	14000	14000	14000	14000	14000	14000	14000	14000	14000	14000	14000	14000	14000
				14000	14000	14000	14000	14000	14000	14000	14000	14000	14000	14000	14000	14000	14000	14000	14000	14000	14000
				14000	14000	14000	14000	14000	14000	14000	14000	14000	14000	14000	14000	14000	14000	14000	14000	14000	14000
				14000	14000	14000	14000	14000	14000	14000	14000	14000	14000	14000	14000	14000	14000	14000	14000	14000	14000
				14000	14000	14000	14000	14000	14000	14000	14000	14000	14000	14000	14000	14000	14000	14000	14000	14000	14000
				14000	14000	14000	14000	14000	14000	14000	14000	14000	14000	14000	14000	14000	14000	14000	14000	14000	14000
				14000	14000	14000	14000	14000	14000	14000	14000	14000	14000	14000	14000	14000	14000	14000	14000	14000	14000
				14000	14000	14000	14000	14000	14000	14000	14000	14000	14000	14000	14000	14000	14000	14000	14000	14000	14000
				14000	14000	14000	14000	14000	14000	14000	14000	14000	14000	14000	14000	14000	14000	14000	14000	14000	14000
				14000	14000	14000	14000	14000	14000	14000	14000	14000	14000	14000	14000	14000	14000	14000	14000	14000	14000
				14000	14000	14000	14000	14000	14000	14000	14000	14000	14000	14000	14000	14000	14000	14000	14000	14000	14000
				14000	14000	14000	14000	14000	14000	14000	14000	14000	14000	14000	14000	14000	14000	14000	14000	14000	14000
				14000	14000	14000	14000	14000	14000	14000	14000	14000	14000	14000	14000	14000	14000	14000	14000	14000	14000
				14000	14000	14000	14000	14000	14000	14000	14000	14000	14000	14000	14000	14000	14000	14000	14000	14000	14000
				14000	14000	14000	14000	14000	14000	14000	14000	14000	14000	14000	14000	14000	14000	14000	14000	14000	14000
				14000	14000	14000	14000	14000	14000	14000	14000	14000	14000	14000	14000	14000	14000	14000	14000	14000	14000
				14000	14000	14000	14000	14000	14000	14000	14000	14000	14000	14000	14000	14000	14000	14000	14000	14000	14000
				14000	14000	14000	14000	14000	14000	14000	14000	14000	14000	14000	14000	14000	14000	14000	14000	14000	14000
				14000	14000	14000	14000	14000	14000	14000	14000	14000	14000	14000	14000	14000	14000	14000	14000	14000	14000
				14000	14000	14000	14000	14000	14000	14000	14000	14000	14000	14000	14000	14000	14000	14000	14000	14000	14000
				14000	14000	14000	14000	14000	14000	14000	14000	14000	14000	14000	14000	14000	14000	14000	14000	14000	14000
				14000	14000	14000	14000	14000	14000	14000	14000	14000	14000	14000	14000	14000	14000	14000	14000	14000	14000
				14000	14000	14000	14000	14000	14000	14000	14000	14000	14000	14000	14000	14000	14000	14000	14000	14000	14000
				14000	14000	14000	14000	14000	14000	14000	14000	14000	14000	14000	14000	14000	14000	14000	14000	14000	14000
				14000	14000	14000	14000	14000	14000	14000	14000	14000	14000	14000	14000	14000	14000	14000	14000	14000	14000
				14000	14000	14000	14000	14000	14000	14000	14000	14000	14000	14000	14000	14000	14000	14000	14000	14000	14000
				14000	14000	14000	14000	14000	14000	14000	14000	14000	14000	14000	14000	14000	14000	14000	14000	14000	14000
				14000	14000	14000	14000	14000	14000	14000	14000	14000	14000	14000	14000	14000	14000	14000	14000	14000	14000
				14000	14000	14000	14000	14000	14000	14000	14000	14000	14000	14000	14000	14000	14000	14000	14000	14000	14000
				14000	14000	14000	14000	14000	14000	14000	14000	14000	14000	14000	14000	14000	14000	14000	14000	14000	14000
				14000	14000	14000>;

			PS_Config_Lmt_Short_Rawdata_N = <
				11000	11000	11000	11000	11000	11000	11000	11000	11000	11000	11000	11000	11000	11000	11000	11000	11000	11000
				11000	11000	11000	11000	11000	11000	11000	11000	11000	11000	11000	11000	11000	11000	11000	11000	11000	11000
				11000	11000	11000	11000	11000	11000	11000	11000	11000	11000	11000	11000	11000	11000	11000	11000	11000	11000
				11000	11000	11000	11000	11000	11000	11000	11000	11000	11000	11000	11000	11000	11000	11000	11000	11000	11000
				11000	11000	11000	11000	11000	11000	11000	11000	11000	11000	11000	11000	11000	11000	11000	11000	11000	11000
				11000	11000	11000	11000	11000	11000	11000	11000	11000	11000	11000	11000	11000	11000	11000	11000	11000	11000
				11000	11000	11000	11000	11000	11000	11000	11000	11000	11000	11000	11000	11000	11000	11000	11000	11000	11000
				11000	11000	11000	11000	11000	11000	11000	11000	11000	11000	11000	11000	11000	11000	11000	11000	11000	11000
				11000	11000	11000	11000	11000	11000	11000	11000	11000	11000	11000	11000	11000	11000	11000	11000	11000	11000
				11000	11000	11000	11000	11000	11000	11000	11000	11000	11000	11000	11000	11000	11000	11000	11000	11000	11000
				11000	11000	11000	11000	11000	11000	11000	11000	11000	11000	11000	11000	11000	11000	11000	11000	11000	11000
				11000	11000	11000	11000	11000	11000	11000	11000	11000	11000	11000	11000	11000	11000	11000	11000	11000	11000
				11000	11000	11000	11000	11000	11000	11000	11000	11000	11000	11000	11000	11000	11000	11000	11000	11000	11000
				11000	11000	11000	11000	11000	11000	11000	11000	11000	11000	11000	11000	11000	11000	11000	11000	11000	11000
				11000	11000	11000	11000	11000	11000	11000	11000	11000	11000	11000	11000	11000	11000	11000	11000	11000	11000
				11000	11000	11000	11000	11000	11000	11000	11000	11000	11000	11000	11000	11000	11000	11000	11000	11000	11000
				11000	11000	11000	11000	11000	11000	11000	11000	11000	11000	11000	11000	11000	11000	11000	11000	11000	11000
				11000	11000	11000	11000	11000	11000	11000	11000	11000	11000	11000	11000	11000	11000	11000	11000	11000	11000
				11000	11000	11000	11000	11000	11000	11000	11000	11000	11000	11000	11000	11000	11000	11000	11000	11000	11000
				11000	11000	11000	11000	11000	11000	11000	11000	11000	11000	11000	11000	11000	11000	11000	11000	11000	11000
				11000	11000	11000	11000	11000	11000	11000	11000	11000	11000	11000	11000	11000	11000	11000	11000	11000	11000
				11000	11000	11000	11000	11000	11000	11000	11000	11000	11000	11000	11000	11000	11000	11000	11000	11000	11000
				11000	11000	11000	11000	11000	11000	11000	11000	11000	11000	11000	11000	11000	11000	11000	11000	11000	11000
				11000	11000	11000	11000	11000	11000	11000	11000	11000	11000	11000	11000	11000	11000	11000	11000	11000	11000
				11000	11000	11000	11000	11000	11000	11000	11000	11000	11000	11000	11000	11000	11000	11000	11000	11000	11000
				11000	11000	11000	11000	11000	11000	11000	11000	11000	11000	11000	11000	11000	11000	11000	11000	11000	11000
				11000	11000	11000	11000	11000	11000	11000	11000	11000	11000	11000	11000	11000	11000	11000	11000	11000	11000
				11000	11000	11000	11000	11000	11000	11000	11000	11000	11000	11000	11000	11000	11000	11000	11000	11000	11000
				11000	11000	11000	11000	11000	11000	11000	11000	11000	11000	11000	11000	11000	11000	11000	11000	11000	11000
				11000	11000	11000	11000	11000	11000	11000	11000	11000	11000	11000	11000	11000	11000	11000	11000	11000	11000
				11000	11000	11000	11000	11000	11000	11000	11000	11000	11000	11000	11000	11000	11000	11000	11000	11000	11000
				11000	11000	11000	11000	11000	11000	11000	11000	11000	11000	11000	11000	11000	11000	11000	11000	11000	11000
				11000	11000	11000	11000	11000	11000	11000	11000	11000	11000	11000	11000	11000	11000	11000	11000	11000	11000
				11000	11000	11000	11000	11000	11000	11000	11000	11000	11000	11000	11000	11000	11000	11000	11000	11000	11000
				11000	11000	11000	11000	11000	11000	11000	11000	11000	11000	11000	11000	11000	11000	11000	11000	11000	11000
				11000	11000	11000	11000	11000	11000	11000	11000	11000	11000	11000	11000	11000	11000	11000	11000	11000	11000
				11000	11000	11000>;

			PS_Config_Lmt_Open_Rawdata_P = <
				1921	2914	3032	3036	3040	3025	3031	2876	65535	65535	2882	3049	3041	3050	3060	3079	2959	1946
				2844	3007	3003	3006	3008	2997	3003	2984	2899	2940	3026	3046	3039	3045	3058	3075	3084	2887
				3053	3018	3014	3017	3018	3008	3014	2995	2979	3014	3027	3048	3042	3048	3063	3079	3086	3092
				3026	3022	3021	3023	3023	3013	3017	2997	2981	3023	3037	3056	3053	3058	3072	3086	3094	3096
				3034	3022	3023	3025	3023	3014	3018	2999	2983	3031	3044	3059	3058	3064	3075	3089	3098	3098
				3037	3036	3039	3037	3036	3027	3031	3011	2995	3034	3046	3060	3059	3067	3077	3089	3100	3097
				3037	3036	3036	3036	3035	3026	3028	3008	2998	3023	3039	3051	3053	3059	3070	3082	3091	3083
				3050	3031	3032	3030	3031	3022	3025	3002	2994	3042	3056	3060	3055	3072	3082	3089	3102	3093
				3049	3027	3030	3027	3028	3021	3023	3001	2994	3049	3061	3069	3063	3078	3089	3098	3105	3096
				3045	3032	3035	3031	3034	3025	3027	3007	2998	3042	3055	3063	3058	3072	3083	3091	3097	3084
				3039	3032	3036	3031	3031	3022	3023	3007	2995	3040	3049	3056	3053	3067	3077	3084	3091	3078
				3042	3022	3027	3022	3022	3013	3016	2998	2989	3040	3048	3055	3054	3068	3074	3082	3089	3075
				3040	3021	3026	3020	3022	3013	3014	2998	2989	3039	3048	3056	3053	3065	3073	3082	3084	3069
				3027	3027	3031	3023	3025	3016	3017	3006	2993	3045	3054	3063	3060	3074	3079	3087	3088	3074
				3026	3017	3027	3018	3021	3011	3016	3006	2990	3032	3040	3053	3049	3063	3068	3077	3075	3061
				3027	3020	3028	3021	3022	3014	3022	3012	2995	3034	3040	3049	3049	3063	3067	3075	3072	3056
				3022	3006	3014	3007	3008	2999	3008	3006	2981	3022	3028	3037	3039	3050	3053	3061	3060	3045
				3023	2994	3004	2997	2997	2988	2995	2990	2971	3022	3030	3037	3037	3049	3050	3060	3056	3046
				3007	2999	3004	2998	2998	2989	2994	2989	2965	3018	3026	3034	3034	3044	3046	3055	3048	3031
				2992	2989	2997	2989	2989	2979	2987	2981	2969	3008	3014	3025	3023	3032	3034	3044	3036	3025
				2997	2981	2988	2980	2979	2970	2978	2973	2961	3013	3017	3028	3026	3036	3036	3045	3041	3027
				2988	2979	2985	2978	2976	2969	2979	2970	2957	3006	3008	3021	3018	3027	3027	3035	3032	3018
				2980	2973	2978	2971	2969	2961	2971	2965	2951	3002	3004	3017	3014	3022	3023	3028	3023	3008
				2978	2962	2967	2960	2959	2951	2961	2955	2941	2990	2997	3008	3006	3013	3012	3018	3014	2998
				2713	2683	2691	2688	2684	2674	2680	2674	2668	2716	2716	2733	2730	2739	2741	2744	2740	2735
				2708	2696	2703	2700	2696	2687	2696	2688	2680	2716	2716	2731	2729	2738	2740	2743	2739	2736
				2687	2684	2689	2684	2683	2674	2683	2678	2670	2707	2708	2724	2721	2730	2734	2735	2734	2729
				2697	2683	2688	2683	2682	2677	2684	2678	2670	2694	2697	2711	2708	2716	2720	2721	2721	2715
				2686	2668	2673	2668	2667	2661	2669	2661	2654	2692	2694	2708	2706	2713	2716	2719	2719	2712
				2683	2663	2668	2663	2660	2655	2664	2655	2649	2684	2686	2697	2694	2703	2706	2710	2711	2706
				2668	2651	2654	2650	2649	2642	2651	2641	2636	2677	2679	2689	2687	2694	2697	2701	2702	2696
				2661	2642	2646	2641	2641	2636	2646	2635	2630	2668	2670	2682	2678	2687	2689	2692	2694	2688
				2650	2632	2635	2630	2631	2623	2636	2623	2618	2653	2655	2664	2661	2670	2672	2675	2678	2670
				2640	2617	2621	2617	2617	2611	2623	2609	2603	2665	2670	2677	2675	2684	2686	2691	2694	2697
				2393	2600	2603	2600	2600	2594	2608	2592	2586	2620	2626	2644	2632	2641	2640	2647	2653	2428
				1564	2505	2630	2630	2633	2626	2640	2622	2621	2642	2642	2663	2651	2661	2658	2664	2546	1601
				4096	4096	4096>;

			PS_Config_Lmt_Open_Rawdata_N = <
				1104	1675	1743	1745	1747	1738	1742	1653	(-65535)	(-65535)	1657	1752	1748	1753	1759	1770	1700	1119
				1635	1728	1726	1727	1729	1722	1726	1715	1666	1689	1739	1751	1746	1750	1757	1768	1773	1660
				1754	1735	1733	1734	1735	1729	1733	1722	1712	1733	1740	1752	1749	1752	1760	1770	1773	1777
				1739	1737	1736	1738	1738	1732	1734	1722	1714	1738	1746	1757	1754	1757	1765	1773	1779	1779
				1743	1737	1738	1738	1738	1733	1735	1724	1714	1742	1749	1758	1757	1761	1768	1776	1781	1781
				1746	1745	1746	1746	1745	1740	1742	1730	1722	1743	1751	1759	1758	1762	1768	1776	1781	1780
				1746	1745	1745	1745	1744	1739	1741	1729	1723	1738	1746	1754	1754	1758	1765	1771	1776	1772
				1753	1742	1743	1741	1742	1737	1738	1725	1721	1749	1757	1759	1756	1765	1771	1776	1783	1778
				1752	1740	1741	1740	1741	1736	1738	1724	1721	1752	1760	1764	1760	1769	1776	1781	1784	1779
				1750	1743	1744	1742	1743	1738	1740	1728	1723	1749	1756	1760	1757	1765	1772	1776	1780	1773
				1746	1743	1745	1742	1742	1737	1738	1728	1722	1747	1752	1757	1754	1762	1768	1773	1776	1769
				1749	1737	1740	1737	1737	1732	1733	1723	1718	1747	1752	1756	1755	1763	1767	1771	1776	1768
				1747	1736	1739	1735	1737	1732	1733	1723	1718	1746	1752	1757	1754	1762	1766	1771	1773	1764
				1740	1740	1742	1738	1738	1733	1734	1727	1720	1750	1755	1760	1759	1767	1770	1774	1775	1767
				1739	1734	1740	1735	1736	1730	1733	1727	1719	1743	1747	1754	1752	1760	1763	1768	1768	1760
				1740	1735	1741	1736	1737	1733	1737	1731	1722	1743	1747	1752	1752	1760	1762	1768	1765	1757
				1737	1727	1733	1728	1729	1724	1729	1727	1714	1737	1741	1746	1746	1753	1754	1760	1759	1750
				1738	1721	1727	1722	1722	1717	1722	1719	1708	1737	1741	1746	1746	1752	1753	1759	1757	1751
				1728	1724	1727	1723	1723	1718	1721	1718	1704	1735	1739	1743	1743	1749	1751	1756	1752	1742
				1719	1718	1722	1718	1718	1712	1716	1714	1706	1729	1733	1738	1738	1743	1743	1749	1745	1738
				1722	1714	1717	1713	1712	1707	1711	1708	1702	1732	1734	1741	1739	1745	1745	1750	1748	1740
				1717	1712	1716	1711	1711	1706	1712	1707	1700	1727	1729	1736	1735	1740	1740	1744	1743	1735
				1713	1708	1711	1708	1706	1702	1708	1704	1696	1725	1727	1734	1733	1737	1738	1741	1738	1729
				1711	1703	1706	1701	1700	1696	1702	1698	1690	1719	1722	1729	1727	1732	1731	1735	1733	1723
				1560	1542	1546	1545	1543	1537	1541	1537	1533	1561	1561	1570	1569	1574	1576	1577	1575	1572
				1557	1549	1554	1551	1549	1544	1549	1545	1541	1561	1561	1570	1568	1573	1575	1576	1574	1573
				1544	1543	1546	1543	1542	1537	1542	1539	1535	1556	1557	1565	1564	1569	1571	1572	1571	1568
				1550	1542	1545	1542	1541	1538	1543	1539	1535	1549	1550	1558	1557	1561	1563	1564	1564	1560
				1543	1533	1536	1533	1533	1530	1534	1530	1525	1547	1549	1557	1555	1560	1561	1562	1562	1559
				1542	1530	1533	1530	1529	1526	1531	1526	1522	1543	1543	1550	1549	1554	1555	1557	1558	1555
				1533	1524	1525	1523	1522	1519	1524	1518	1515	1538	1540	1546	1544	1549	1550	1552	1553	1549
				1530	1519	1521	1518	1518	1515	1521	1514	1511	1533	1535	1541	1539	1544	1546	1547	1549	1545
				1523	1513	1514	1511	1512	1508	1515	1508	1505	1524	1526	1531	1530	1535	1535	1538	1539	1535
				1517	1504	1506	1504	1504	1500	1508	1500	1496	1532	1535	1538	1538	1543	1543	1546	1549	1550
				1376	1495	1496	1495	1495	1491	1499	1489	1487	1505	1509	1519	1513	1518	1517	1522	1524	1395
				899	1440	1511	1511	1514	1509	1517	1507	1506	1519	1519	1530	1524	1530	1527	1531	1463	920
				50 50 50>;

			PS_Config_Lmt_FW_Rawdata_P = <
				2216	2231	2227	2224	2252	2213	2207	2219	65535	65535	2245	2241	2237	2227	2248	2217	2238	2220
				2241	2224	2242	2217	2219	2221	2214	2224	2223	2226	2210	2216	2212	2210	2220	2213	2206	2254
				2223	2214	2217	2213	2235	2242	2227	2228	2214	2240	2227	2206	2234	2240	2205	2224	2228	2238
				2221	2210	2242	2209	2200	2241	2238	2231	2226	2220	2219	2248	2206	2213	2235	2237	2221	2223
				2240	2210	2247	2231	2207	2219	2270	2270	2238	2231	2209	2234	2219	2210	2241	2234	2202	2206
				2242	2254	2219	2192	2235	2224	2213	2224	2207	2210	2219	2237	2203	2185	2214	2237	2242	2227
				2233	2223	2221	2189	2251	2240	2242	2233	2223	2216	2210	2235	2213	2191	2221	2242	2221	2223
				2210	2212	2249	2234	2203	2213	2223	2259	2251	2228	2230	2228	2234	2221	2248	2242	2209	2223
				2252	2230	2212	2231	2221	2207	2217	2221	2234	2223	2212	2227	2216	2210	2231	2230	2227	2231
				2210	2244	2210	2213	2234	2220	2235	2213	2203	2235	2191	2202	2233	2237	2216	2199	2213	2254
				2223	2227	2220	2230	2233	2237	2241	2230	2228	2212	2213	2234	2184	2182	2233	2247	2235	2205
				2210	2226	2199	2213	2245	2221	2234	2228	2210	2248	2228	2231	2233	2235	2230	2224	2227	2233
				2228	2235	2228	2219	2200	2247	2214	2220	2244	2235	2233	2227	2234	2241	2199	2202	2221	2242
				2237	2223	2216	2223	2231	2219	2228	2223	2207	2259	2223	2224	2212	2217	2219	2248	2209	2242
				2240	2214	2213	2240	2241	2240	2235	2213	2227	2251	2226	2235	2220	2216	2230	2228	2221	2230
				2219	2238	2205	2191	2234	2249	2237	2217	2210	2247	2241	2221	2207	2212	2241	2251	2195	2227
				2238	2214	2233	2227	2205	2213	2207	2238	2245	2240	2227	2209	2195	2206	2240	2242	2200	2230
				2210	2234	2233	2240	2206	2216	2212	2221	2233	2226	2238	2224	2230	2233	2200	2209	2241	2212
				2252	2213	2214	2206	2234	2230	2237	2237	2226	2227	2230	2219	2220	2214	2234	2240	2234	2233
				2220	2226	2216	2213	2224	2227	2230	2205	2219	2231	2228	2224	2214	2234	2216	2226	2214	2223
				2258	2199	2235	2242	2217	2220	2220	2219	2213	2224	2221	2216	2230	2223	2224	2207	2217	2238
				2210	2234	2235	2223	2207	2214	2210	2212	2231	2210	2227	2217	2206	2219	2226	2223	2207	2244
				2244	2209	2237	2227	2206	2205	2217	2210	2241	2231	2199	2198	2206	2214	2245	2242	2214	2242
				2223	2224	2216	2206	2252	2242	2213	2185	2217	2258	2261	2254	2249	2221	2202	2209	2258	2207
				2219	2221	2227	2223	2217	2223	2217	2203	2231	2209	2220	2230	2241	2217	2214	2219	2221	2242
				2242	2231	2220	2214	2224	2223	2224	2224	2216	2231	2200	2227	2207	2248	2247	2189	2249	2216
				2234	2209	2202	2217	2241	2224	2213	2221	2221	2209	2212	2217	2216	2226	2235	2230	2231	2203
				2224	2230	2233	2224	2216	2203	2220	2228	2209	2245	2217	2238	2242	2238	2219	2221	2247	2199
				2241	2241	2224	2227	2210	2216	2224	2228	2220	2224	2209	2213	2221	2209	2231	2226	2230	2247
				2217	2210	2220	2241	2235	2242	2237	2200	2199	2230	2212	2210	2209	2238	2235	2223	2251	2223
				2254	2195	2230	2234	2210	2221	2210	2212	2256	2209	2228	2227	2216	2224	2233	2227	2240	2207
				2228	2219	2203	2220	2227	2238	2205	2219	2212	2234	2224	2224	2226	2217	2244	2233	2242	2207
				2231	2212	2237	2231	2224	2221	2210	2217	2230	2205	2207	2220	2202	2226	2219	2209	2219	2221
				2220	2230	2230	2234	2227	2230	2219	2217	2202	2199	2224	2193	2200	2228	2216	2235	2247	2227
				2230	2241	2206	2199	2234	2234	2217	2214	2219	2241	2205	2199	2224	2202	2206	2227	2227	2247
				2223	2231	2219	2214	2212	2216	2223	2226	2221	2240	2235	2221	2206	2193	2209	2192	2228	2206
				1920	1920	1920>;

			PS_Config_Lmt_FW_Rawdata_N = <
				949	956	954	953	965	948	946	951	(-65535)	(-65535)	962	960	958	954	963	950	959	951
				960	953	961	950	951	952	949	953	952	954	947	949	948	947	951	948	945	966
				952	949	950	948	958	961	954	955	949	960	954	945	957	960	945	953	955	959
				952	947	961	946	943	960	959	956	954	951	951	963	945	948	958	958	952	952
				960	947	963	956	946	951	973	973	959	956	946	957	951	947	960	957	943	945
				961	966	951	939	958	953	948	953	946	947	951	958	944	936	949	958	961	954
				957	952	952	938	964	960	961	957	952	949	947	958	948	939	952	961	952	952
				947	948	964	957	944	948	952	968	964	955	955	955	957	952	963	961	946	952
				965	955	948	956	952	946	950	952	957	952	948	954	949	947	956	955	954	956
				947	961	947	948	957	951	958	948	944	958	939	943	957	958	949	942	948	966
				952	954	951	955	957	958	960	955	955	948	948	957	936	935	957	963	958	945
				947	954	942	948	962	952	957	955	947	963	955	956	957	958	955	953	954	957
				955	958	955	951	943	963	949	951	961	958	957	954	957	960	942	943	952	961
				958	952	949	952	956	951	955	952	946	968	952	953	948	950	951	963	946	961
				960	949	948	960	960	960	958	948	954	964	954	958	951	949	955	955	952	955
				951	959	945	939	957	964	958	950	947	963	960	952	946	948	960	964	940	954
				959	949	957	954	945	948	946	959	962	960	954	946	940	945	960	961	943	955
				947	957	957	960	945	949	948	952	957	954	959	953	955	957	943	946	960	948
				965	948	949	945	957	955	958	958	954	954	955	951	951	949	957	960	957	957
				951	954	949	948	953	954	955	945	951	956	955	953	949	957	949	954	949	952
				967	942	958	961	950	951	951	951	948	953	952	949	955	952	953	946	950	959
				947	957	958	952	946	949	947	948	956	947	954	950	945	951	954	952	946	961
				961	946	958	954	945	945	950	947	960	956	942	942	945	949	962	961	949	961
				952	953	949	945	965	961	948	936	950	967	969	966	964	952	943	946	967	946
				951	952	954	952	950	952	950	944	956	946	951	955	960	950	949	951	952	961
				961	956	951	949	953	952	953	953	949	956	943	954	946	963	963	938	964	949
				957	946	943	950	960	953	948	952	952	946	948	950	949	954	958	955	956	944
				953	955	957	953	949	944	951	955	946	962	950	959	961	959	951	952	963	942
				960	960	953	954	947	949	953	955	951	953	946	948	952	946	956	954	955	963
				950	947	951	960	958	961	958	943	942	955	948	947	946	959	958	952	964	952
				966	940	955	957	947	952	947	948	967	946	955	954	949	953	957	954	960	946
				955	951	944	951	954	959	945	951	948	957	953	953	954	950	961	957	961	946
				956	948	958	956	953	952	947	950	955	945	946	951	943	954	951	946	951	952
				951	955	955	957	954	955	951	950	943	942	953	940	943	955	949	958	963	954
				955	960	945	942	957	957	950	949	951	960	945	942	953	943	945	954	954	963
				952	956	951	949	948	949	952	954	952	960	958	952	945	940	946	939	955	945
				240	240	240>;

			PS_Config_Lmt_FW_CC_P = <
				110	124	122	122	121	120	120	120	65535	65535	112	112	110	110	111	112	110	107
				122	112	110	110	109	107	107	107	107	107	110	109	107	107	107	109	110	111
				128	110	107	107	106	105	105	105	105	105	109	107	107	106	107	107	109	111
				116	110	109	109	107	107	106	106	106	107	110	110	109	109	110	110	111	114
				114	110	107	107	107	106	105	105	105	105	109	107	106	106	107	107	109	111
				115	111	110	110	109	107	107	107	107	107	110	109	109	107	109	109	110	112
				114	110	107	107	106	105	105	105	105	107	110	109	107	107	107	109	110	112
				115	110	109	109	107	107	107	106	106	111	111	110	109	109	110	110	110	114
				112	110	109	107	107	106	107	106	105	111	109	107	107	107	107	109	109	111
				115	111	110	110	109	107	109	107	107	112	109	107	107	107	107	107	109	112
				114	109	107	107	106	105	106	105	105	112	107	107	107	107	107	109	109	112
				115	109	107	107	106	106	106	106	105	115	110	110	109	110	110	110	111	115
				112	109	107	107	107	106	106	106	105	112	107	107	107	107	107	109	109	112
				112	110	110	110	109	109	109	110	107	114	109	109	109	109	109	109	110	114
				112	109	107	107	106	106	106	107	105	112	109	109	107	107	109	110	110	112
				115	110	109	109	107	107	107	110	107	114	110	110	109	110	110	110	111	115
				112	110	109	109	107	107	107	109	106	112	107	107	106	106	107	107	109	112
				114	110	110	110	109	109	109	109	107	112	110	109	107	107	109	110	110	114
				112	109	107	107	106	106	106	106	105	112	110	107	107	107	109	109	110	114
				114	110	109	109	107	107	107	107	110	114	110	110	110	110	110	111	111	115
				112	109	107	107	107	107	107	107	107	111	109	107	106	107	107	109	110	114
				112	110	110	110	109	109	110	109	109	112	109	107	107	107	109	109	110	115
				112	107	107	107	106	106	107	107	105	111	109	109	107	109	109	110	110	115
				114	109	109	109	107	107	107	109	106	112	110	110	110	110	111	112	112	117
				111	109	107	107	107	106	107	107	105	109	106	107	107	107	109	109	110	115
				111	110	110	110	110	110	110	110	109	110	109	109	109	110	110	110	112	116
				111	109	109	107	107	107	107	109	106	109	107	107	107	109	110	110	111	115
				114	110	110	110	109	109	110	111	107	110	109	110	110	110	111	112	112	117
				112	110	110	109	107	107	109	110	107	107	107	107	107	107	110	110	111	115
				112	111	111	110	110	110	110	111	109	110	107	109	109	110	110	111	112	117
				112	110	107	107	107	107	107	109	105	109	107	107	107	109	110	110	112	116
				114	110	110	110	109	109	110	110	107	110	109	109	110	110	111	112	114	119
				111	110	110	109	107	107	110	110	106	107	107	106	107	107	109	110	112	116
				112	111	111	110	110	110	112	111	109	117	119	117	119	120	120	121	124	132
				111	110	109	109	107	107	110	109	106	106	110	111	107	107	109	109	110	111
				110	121	120	120	120	120	122	122	122	120	120	121	117	117	117	117	119	116
				314 314 314>;

			PS_Config_Lmt_FW_CC_N = <
				67	76	75	75	74	73	73	73	(-65535)	(-65535)	69	69	67	67	68	69	67	66
				75	69	67	67	66	66	66	66	66	66	67	66	66	66	66	66	67	68
				79	67	66	66	65	64	64	64	64	64	66	66	66	65	66	66	66	68
				71	67	66	66	66	66	65	65	65	66	67	67	66	66	67	67	68	69
				69	67	66	66	66	65	64	64	64	64	66	66	65	65	66	66	66	68
				70	68	67	67	66	66	66	66	66	66	67	66	66	66	66	66	67	69
				69	67	66	66	65	64	64	64	64	66	67	66	66	66	66	66	67	69
				70	67	66	66	66	66	66	65	65	68	68	67	66	66	67	67	67	69
				69	67	66	66	66	65	66	65	64	68	66	66	66	66	66	66	66	68
				70	68	67	67	66	66	66	66	66	69	66	66	66	66	66	66	66	69
				69	66	66	66	65	64	65	64	64	69	66	66	66	66	66	66	66	69
				70	66	66	66	65	65	65	65	64	70	67	67	66	67	67	67	68	70
				69	66	66	66	66	65	65	65	64	69	66	66	66	66	66	66	66	69
				69	67	67	67	66	66	66	67	66	69	66	66	66	66	66	66	67	69
				69	66	66	66	65	65	65	66	64	69	66	66	66	66	66	67	67	69
				70	67	66	66	66	66	66	67	66	69	67	67	66	67	67	67	68	70
				69	67	66	66	66	66	66	66	65	69	66	66	65	65	66	66	66	69
				69	67	67	67	66	66	66	66	66	69	67	66	66	66	66	67	67	69
				69	66	66	66	65	65	65	65	64	69	67	66	66	66	66	66	67	69
				69	67	66	66	66	66	66	66	67	69	67	67	67	67	67	68	68	70
				69	66	66	66	66	66	66	66	66	68	66	66	65	66	66	66	67	69
				69	67	67	67	66	66	67	66	66	69	66	66	66	66	66	66	67	70
				69	66	66	66	65	65	66	66	64	68	66	66	66	66	66	67	67	70
				69	66	66	66	66	66	66	66	65	69	67	67	67	67	68	69	69	72
				68	66	66	66	66	65	66	66	64	66	65	66	66	66	66	66	67	70
				68	67	67	67	67	67	67	67	66	67	66	66	66	67	67	67	69	71
				68	66	66	66	66	66	66	66	65	66	66	66	66	66	67	67	68	70
				69	67	67	67	66	66	67	68	66	67	66	67	67	67	68	69	69	72
				69	67	67	66	66	66	66	67	66	66	66	66	66	66	67	67	68	70
				69	68	68	67	67	67	67	68	66	67	66	66	66	67	67	68	69	72
				69	67	66	66	66	66	66	66	64	66	66	66	66	66	67	67	69	71
				69	67	67	67	66	66	67	67	66	67	66	66	67	67	68	69	69	72
				68	67	67	66	66	66	67	67	65	66	66	65	66	66	66	67	69	71
				69	68	68	67	67	67	69	68	66	72	72	72	72	73	73	74	76	81
				68	67	66	66	66	66	67	66	65	65	67	68	66	66	66	66	67	68
				67	74	73	73	73	73	75	75	75	73	73	74	72	72	72	72	72	71
				30	30	30>;

			PS_Config_Lmt_FW_Diff_P = <
				50	50	50	50	50	50	50	50	65535	65535	50	50	50	50	50	50	50	50
				50	50	50	50	50	50	50	50	50	50	50	50	50	50	50	50	50	50
				50	50	50	50	50	50	50	50	50	50	50	50	50	50	50	50	50	50
				50	50	50	50	50	50	50	50	50	50	50	50	50	50	50	50	50	50
				50	50	50	50	50	50	50	50	50	50	50	50	50	50	50	50	50	50
				50	50	50	50	50	50	50	50	50	50	50	50	50	50	50	50	50	50
				50	50	50	50	50	50	50	50	50	50	50	50	50	50	50	50	50	50
				50	50	50	50	50	50	50	50	50	50	50	50	50	50	50	50	50	50
				50	50	50	50	50	50	50	50	50	50	50	50	50	50	50	50	50	50
				50	50	50	50	50	50	50	50	50	50	50	50	50	50	50	50	50	50
				50	50	50	50	50	50	50	50	50	50	50	50	50	50	50	50	50	50
				50	50	50	50	50	50	50	50	50	50	50	50	50	50	50	50	50	50
				50	50	50	50	50	50	50	50	50	50	50	50	50	50	50	50	50	50
				50	50	50	50	50	50	50	50	50	50	50	50	50	50	50	50	50	50
				50	50	50	50	50	50	50	50	50	50	50	50	50	50	50	50	50	50
				50	50	50	50	50	50	50	50	50	50	50	50	50	50	50	50	50	50
				50	50	50	50	50	50	50	50	50	50	50	50	50	50	50	50	50	50
				50	50	50	50	50	50	50	50	50	50	50	50	50	50	50	50	50	50
				50	50	50	50	50	50	50	50	50	50	50	50	50	50	50	50	50	50
				50	50	50	50	50	50	50	50	50	50	50	50	50	50	50	50	50	50
				50	50	50	50	50	50	50	50	50	50	50	50	50	50	50	50	50	50
				50	50	50	50	50	50	50	50	50	50	50	50	50	50	50	50	50	50
				50	50	50	50	50	50	50	50	50	50	50	50	50	50	50	50	50	50
				50	50	50	50	50	50	50	50	50	50	50	50	50	50	50	50	50	50
				50	50	50	50	50	50	50	50	50	50	50	50	50	50	50	50	50	50
				50	50	50	50	50	50	50	50	50	50	50	50	50	50	50	50	50	50
				50	50	50	50	50	50	50	50	50	50	50	50	50	50	50	50	50	50
				50	50	50	50	50	50	50	50	50	50	50	50	50	50	50	50	50	50
				50	50	50	50	50	50	50	50	50	50	50	50	50	50	50	50	50	50
				50	50	50	50	50	50	50	50	50	50	50	50	50	50	50	50	50	50
				50	50	50	50	50	50	50	50	50	50	50	50	50	50	50	50	50	50
				50	50	50	50	50	50	50	50	50	50	50	50	50	50	50	50	50	50
				50	50	50	50	50	50	50	50	50	50	50	50	50	50	50	50	50	50
				50	50	50	50	50	50	50	50	50	50	50	50	50	50	50	50	50	50
				50	50	50	50	50	50	50	50	50	50	50	50	50	50	50	50	50	50
				50	50	50	50	50	50	50	50	50	50	50	50	50	50	50	50	50	50
				75	75	75>;

			PS_Config_Lmt_FW_Diff_N = <
				(-50)	(-50)	(-50)	(-50)	(-50)	(-50)	(-50)	(-50)	(-65535)	(-65535)	(-50)	(-50)	(-50)	(-50)	(-50)	(-50)	(-50)	(-50)
				(-50)	(-50)	(-50)	(-50)	(-50)	(-50)	(-50)	(-50)	(-50)	(-50)	(-50)	(-50)	(-50)	(-50)	(-50)	(-50)	(-50)	(-50)
				(-50)	(-50)	(-50)	(-50)	(-50)	(-50)	(-50)	(-50)	(-50)	(-50)	(-50)	(-50)	(-50)	(-50)	(-50)	(-50)	(-50)	(-50)
				(-50)	(-50)	(-50)	(-50)	(-50)	(-50)	(-50)	(-50)	(-50)	(-50)	(-50)	(-50)	(-50)	(-50)	(-50)	(-50)	(-50)	(-50)
				(-50)	(-50)	(-50)	(-50)	(-50)	(-50)	(-50)	(-50)	(-50)	(-50)	(-50)	(-50)	(-50)	(-50)	(-50)	(-50)	(-50)	(-50)
				(-50)	(-50)	(-50)	(-50)	(-50)	(-50)	(-50)	(-50)	(-50)	(-50)	(-50)	(-50)	(-50)	(-50)	(-50)	(-50)	(-50)	(-50)
				(-50)	(-50)	(-50)	(-50)	(-50)	(-50)	(-50)	(-50)	(-50)	(-50)	(-50)	(-50)	(-50)	(-50)	(-50)	(-50)	(-50)	(-50)
				(-50)	(-50)	(-50)	(-50)	(-50)	(-50)	(-50)	(-50)	(-50)	(-50)	(-50)	(-50)	(-50)	(-50)	(-50)	(-50)	(-50)	(-50)
				(-50)	(-50)	(-50)	(-50)	(-50)	(-50)	(-50)	(-50)	(-50)	(-50)	(-50)	(-50)	(-50)	(-50)	(-50)	(-50)	(-50)	(-50)
				(-50)	(-50)	(-50)	(-50)	(-50)	(-50)	(-50)	(-50)	(-50)	(-50)	(-50)	(-50)	(-50)	(-50)	(-50)	(-50)	(-50)	(-50)
				(-50)	(-50)	(-50)	(-50)	(-50)	(-50)	(-50)	(-50)	(-50)	(-50)	(-50)	(-50)	(-50)	(-50)	(-50)	(-50)	(-50)	(-50)
				(-50)	(-50)	(-50)	(-50)	(-50)	(-50)	(-50)	(-50)	(-50)	(-50)	(-50)	(-50)	(-50)	(-50)	(-50)	(-50)	(-50)	(-50)
				(-50)	(-50)	(-50)	(-50)	(-50)	(-50)	(-50)	(-50)	(-50)	(-50)	(-50)	(-50)	(-50)	(-50)	(-50)	(-50)	(-50)	(-50)
				(-50)	(-50)	(-50)	(-50)	(-50)	(-50)	(-50)	(-50)	(-50)	(-50)	(-50)	(-50)	(-50)	(-50)	(-50)	(-50)	(-50)	(-50)
				(-50)	(-50)	(-50)	(-50)	(-50)	(-50)	(-50)	(-50)	(-50)	(-50)	(-50)	(-50)	(-50)	(-50)	(-50)	(-50)	(-50)	(-50)
				(-50)	(-50)	(-50)	(-50)	(-50)	(-50)	(-50)	(-50)	(-50)	(-50)	(-50)	(-50)	(-50)	(-50)	(-50)	(-50)	(-50)	(-50)
				(-50)	(-50)	(-50)	(-50)	(-50)	(-50)	(-50)	(-50)	(-50)	(-50)	(-50)	(-50)	(-50)	(-50)	(-50)	(-50)	(-50)	(-50)
				(-50)	(-50)	(-50)	(-50)	(-50)	(-50)	(-50)	(-50)	(-50)	(-50)	(-50)	(-50)	(-50)	(-50)	(-50)	(-50)	(-50)	(-50)
				(-50)	(-50)	(-50)	(-50)	(-50)	(-50)	(-50)	(-50)	(-50)	(-50)	(-50)	(-50)	(-50)	(-50)	(-50)	(-50)	(-50)	(-50)
				(-50)	(-50)	(-50)	(-50)	(-50)	(-50)	(-50)	(-50)	(-50)	(-50)	(-50)	(-50)	(-50)	(-50)	(-50)	(-50)	(-50)	(-50)
				(-50)	(-50)	(-50)	(-50)	(-50)	(-50)	(-50)	(-50)	(-50)	(-50)	(-50)	(-50)	(-50)	(-50)	(-50)	(-50)	(-50)	(-50)
				(-50)	(-50)	(-50)	(-50)	(-50)	(-50)	(-50)	(-50)	(-50)	(-50)	(-50)	(-50)	(-50)	(-50)	(-50)	(-50)	(-50)	(-50)
				(-50)	(-50)	(-50)	(-50)	(-50)	(-50)	(-50)	(-50)	(-50)	(-50)	(-50)	(-50)	(-50)	(-50)	(-50)	(-50)	(-50)	(-50)
				(-50)	(-50)	(-50)	(-50)	(-50)	(-50)	(-50)	(-50)	(-50)	(-50)	(-50)	(-50)	(-50)	(-50)	(-50)	(-50)	(-50)	(-50)
				(-50)	(-50)	(-50)	(-50)	(-50)	(-50)	(-50)	(-50)	(-50)	(-50)	(-50)	(-50)	(-50)	(-50)	(-50)	(-50)	(-50)	(-50)
				(-50)	(-50)	(-50)	(-50)	(-50)	(-50)	(-50)	(-50)	(-50)	(-50)	(-50)	(-50)	(-50)	(-50)	(-50)	(-50)	(-50)	(-50)
				(-50)	(-50)	(-50)	(-50)	(-50)	(-50)	(-50)	(-50)	(-50)	(-50)	(-50)	(-50)	(-50)	(-50)	(-50)	(-50)	(-50)	(-50)
				(-50)	(-50)	(-50)	(-50)	(-50)	(-50)	(-50)	(-50)	(-50)	(-50)	(-50)	(-50)	(-50)	(-50)	(-50)	(-50)	(-50)	(-50)
				(-50)	(-50)	(-50)	(-50)	(-50)	(-50)	(-50)	(-50)	(-50)	(-50)	(-50)	(-50)	(-50)	(-50)	(-50)	(-50)	(-50)	(-50)
				(-50)	(-50)	(-50)	(-50)	(-50)	(-50)	(-50)	(-50)	(-50)	(-50)	(-50)	(-50)	(-50)	(-50)	(-50)	(-50)	(-50)	(-50)
				(-50)	(-50)	(-50)	(-50)	(-50)	(-50)	(-50)	(-50)	(-50)	(-50)	(-50)	(-50)	(-50)	(-50)	(-50)	(-50)	(-50)	(-50)
				(-50)	(-50)	(-50)	(-50)	(-50)	(-50)	(-50)	(-50)	(-50)	(-50)	(-50)	(-50)	(-50)	(-50)	(-50)	(-50)	(-50)	(-50)
				(-50)	(-50)	(-50)	(-50)	(-50)	(-50)	(-50)	(-50)	(-50)	(-50)	(-50)	(-50)	(-50)	(-50)	(-50)	(-50)	(-50)	(-50)
				(-50)	(-50)	(-50)	(-50)	(-50)	(-50)	(-50)	(-50)	(-50)	(-50)	(-50)	(-50)	(-50)	(-50)	(-50)	(-50)	(-50)	(-50)
				(-50)	(-50)	(-50)	(-50)	(-50)	(-50)	(-50)	(-50)	(-50)	(-50)	(-50)	(-50)	(-50)	(-50)	(-50)	(-50)	(-50)	(-50)
				(-50)	(-50)	(-50)	(-50)	(-50)	(-50)	(-50)	(-50)	(-50)	(-50)	(-50)	(-50)	(-50)	(-50)	(-50)	(-50)	(-50)	(-50)
				(-75)	(-75)	(-75)>;

			PS_Config_Diff_Test_Frame = <50>;
		};/*}}}*/

		/* for Xiaomi C3X 672A EBBG 6.3" */
		novatek-mp-criteria-5927@0 {/*{{{*/
			#address-cells = <1>;
			#size-cells = <0>;
			compatible = "novatek-mp-criteria-5927";

			/* MP Config */
			IC_X_CFG_SIZE = <18>;
			IC_Y_CFG_SIZE = <36>;
			IC_KEY_CFG_SIZE = <4>;
			X_Channel = <18>;
			Y_Channel = <36>;
			AIN_X = <0 1 2 3 4 5 6 7 8 9 10 11 12 13 14 15 16 17>;
			AIN_Y = <0 1 2 3 4 5 6 7 8 9 10 11 12 13 14 15 16 17
						18 19 20 21 22 23 24 25 26 27 28 29 30 31 32 33 34 35>;
			AIN_KEY = <0 1 2 0xFF>;

			/* MP Criteria */
			PS_Config_Lmt_Short_Rawdata_P = <
				14000 14000 14000 14000 14000 14000 14000 14000 14000 14000 14000 14000 14000 14000 14000 14000 14000 14000  
				14000 14000 14000 14000 14000 14000 14000 14000 14000 14000 14000 14000 14000 14000 14000 14000 14000 14000
				14000 14000 14000 14000 14000 14000 14000 14000 14000 14000 14000 14000 14000 14000 14000 14000 14000 14000
				14000 14000 14000 14000 14000 14000 14000 14000 14000 14000 14000 14000 14000 14000 14000 14000 14000 14000
				14000 14000 14000 14000 14000 14000 14000 14000 14000 14000 14000 14000 14000 14000 14000 14000 14000 14000
				14000 14000 14000 14000 14000 14000 14000 14000 14000 14000 14000 14000 14000 14000 14000 14000 14000 14000
				14000 14000 14000 14000 14000 14000 14000 14000 14000 14000 14000 14000 14000 14000 14000 14000 14000 14000
				14000 14000 14000 14000 14000 14000 14000 14000 14000 14000 14000 14000 14000 14000 14000 14000 14000 14000
				14000 14000 14000 14000 14000 14000 14000 14000 14000 14000 14000 14000 14000 14000 14000 14000 14000 14000
				14000 14000 14000 14000 14000 14000 14000 14000 14000 14000 14000 14000 14000 14000 14000 14000 14000 14000
				14000 14000 14000 14000 14000 14000 14000 14000 14000 14000 14000 14000 14000 14000 14000 14000 14000 14000
				14000 14000 14000 14000 14000 14000 14000 14000 14000 14000 14000 14000 14000 14000 14000 14000 14000 14000
				14000 14000 14000 14000 14000 14000 14000 14000 14000 14000 14000 14000 14000 14000 14000 14000 14000 14000
				14000 14000 14000 14000 14000 14000 14000 14000 14000 14000 14000 14000 14000 14000 14000 14000 14000 14000
				14000 14000 14000 14000 14000 14000 14000 14000 14000 14000 14000 14000 14000 14000 14000 14000 14000 14000
				14000 14000 14000 14000 14000 14000 14000 14000 14000 14000 14000 14000 14000 14000 14000 14000 14000 14000
				14000 14000 14000 14000 14000 14000 14000 14000 14000 14000 14000 14000 14000 14000 14000 14000 14000 14000
				14000 14000 14000 14000 14000 14000 14000 14000 14000 14000 14000 14000 14000 14000 14000 14000 14000 14000
				14000 14000 14000 14000 14000 14000 14000 14000 14000 14000 14000 14000 14000 14000 14000 14000 14000 14000
				14000 14000 14000 14000 14000 14000 14000 14000 14000 14000 14000 14000 14000 14000 14000 14000 14000 14000
				14000 14000 14000 14000 14000 14000 14000 14000 14000 14000 14000 14000 14000 14000 14000 14000 14000 14000
				14000 14000 14000 14000 14000 14000 14000 14000 14000 14000 14000 14000 14000 14000 14000 14000 14000 14000
				14000 14000 14000 14000 14000 14000 14000 14000 14000 14000 14000 14000 14000 14000 14000 14000 14000 14000
				14000 14000 14000 14000 14000 14000 14000 14000 14000 14000 14000 14000 14000 14000 14000 14000 14000 14000
				14000 14000 14000 14000 14000 14000 14000 14000 14000 14000 14000 14000 14000 14000 14000 14000 14000 14000
				14000 14000 14000 14000 14000 14000 14000 14000 14000 14000 14000 14000 14000 14000 14000 14000 14000 14000
				14000 14000 14000 14000 14000 14000 14000 14000 14000 14000 14000 14000 14000 14000 14000 14000 14000 14000
				14000 14000 14000 14000 14000 14000 14000 14000 14000 14000 14000 14000 14000 14000 14000 14000 14000 14000
				14000 14000 14000 14000 14000 14000 14000 14000 14000 14000 14000 14000 14000 14000 14000 14000 14000 14000
				14000 14000 14000 14000 14000 14000 14000 14000 14000 14000 14000 14000 14000 14000 14000 14000 14000 14000
				14000 14000 14000 14000 14000 14000 14000 14000 14000 14000 14000 14000 14000 14000 14000 14000 14000 14000
				14000 14000 14000 14000 14000 14000 14000 14000 14000 14000 14000 14000 14000 14000 14000 14000 14000 14000
				14000 14000 14000 14000 14000 14000 14000 14000 14000 14000 14000 14000 14000 14000 14000 14000 14000 14000
				14000 14000 14000 14000 14000 14000 14000 14000 14000 14000 14000 14000 14000 14000 14000 14000 14000 14000
				14000 14000 14000 14000 14000 14000 14000 14000 14000 14000 14000 14000 14000 14000 14000 14000 14000 14000
				14000 14000 14000 14000 14000 14000 14000 14000 14000 14000 14000 14000 14000 14000 14000 14000 14000 14000
				14000 14000 14000>;

			PS_Config_Lmt_Short_Rawdata_N = <
				11000 11000 11000 11000 11000 11000 11000 11000 11000 11000 11000 11000 11000 11000 11000 11000 11000 11000
				11000 11000 11000 11000 11000 11000 11000 11000 11000 11000 11000 11000 11000 11000 11000 11000 11000 11000
				11000 11000 11000 11000 11000 11000 11000 11000 11000 11000 11000 11000 11000 11000 11000 11000 11000 11000
				11000 11000 11000 11000 11000 11000 11000 11000 11000 11000 11000 11000 11000 11000 11000 11000 11000 11000
				11000 11000 11000 11000 11000 11000 11000 11000 11000 11000 11000 11000 11000 11000 11000 11000 11000 11000
				11000 11000 11000 11000 11000 11000 11000 11000 11000 11000 11000 11000 11000 11000 11000 11000 11000 11000
				11000 11000 11000 11000 11000 11000 11000 11000 11000 11000 11000 11000 11000 11000 11000 11000 11000 11000
				11000 11000 11000 11000 11000 11000 11000 11000 11000 11000 11000 11000 11000 11000 11000 11000 11000 11000
				11000 11000 11000 11000 11000 11000 11000 11000 11000 11000 11000 11000 11000 11000 11000 11000 11000 11000
				11000 11000 11000 11000 11000 11000 11000 11000 11000 11000 11000 11000 11000 11000 11000 11000 11000 11000
				11000 11000 11000 11000 11000 11000 11000 11000 11000 11000 11000 11000 11000 11000 11000 11000 11000 11000
				11000 11000 11000 11000 11000 11000 11000 11000 11000 11000 11000 11000 11000 11000 11000 11000 11000 11000
				11000 11000 11000 11000 11000 11000 11000 11000 11000 11000 11000 11000 11000 11000 11000 11000 11000 11000
				11000 11000 11000 11000 11000 11000 11000 11000 11000 11000 11000 11000 11000 11000 11000 11000 11000 11000
				11000 11000 11000 11000 11000 11000 11000 11000 11000 11000 11000 11000 11000 11000 11000 11000 11000 11000
				11000 11000 11000 11000 11000 11000 11000 11000 11000 11000 11000 11000 11000 11000 11000 11000 11000 11000
				11000 11000 11000 11000 11000 11000 11000 11000 11000 11000 11000 11000 11000 11000 11000 11000 11000 11000
				11000 11000 11000 11000 11000 11000 11000 11000 11000 11000 11000 11000 11000 11000 11000 11000 11000 11000
				11000 11000 11000 11000 11000 11000 11000 11000 11000 11000 11000 11000 11000 11000 11000 11000 11000 11000
				11000 11000 11000 11000 11000 11000 11000 11000 11000 11000 11000 11000 11000 11000 11000 11000 11000 11000
				11000 11000 11000 11000 11000 11000 11000 11000 11000 11000 11000 11000 11000 11000 11000 11000 11000 11000
				11000 11000 11000 11000 11000 11000 11000 11000 11000 11000 11000 11000 11000 11000 11000 11000 11000 11000
				11000 11000 11000 11000 11000 11000 11000 11000 11000 11000 11000 11000 11000 11000 11000 11000 11000 11000
				11000 11000 11000 11000 11000 11000 11000 11000 11000 11000 11000 11000 11000 11000 11000 11000 11000 11000
				11000 11000 11000 11000 11000 11000 11000 11000 11000 11000 11000 11000 11000 11000 11000 11000 11000 11000
				11000 11000 11000 11000 11000 11000 11000 11000 11000 11000 11000 11000 11000 11000 11000 11000 11000 11000
				11000 11000 11000 11000 11000 11000 11000 11000 11000 11000 11000 11000 11000 11000 11000 11000 11000 11000
				11000 11000 11000 11000 11000 11000 11000 11000 11000 11000 11000 11000 11000 11000 11000 11000 11000 11000
				11000 11000 11000 11000 11000 11000 11000 11000 11000 11000 11000 11000 11000 11000 11000 11000 11000 11000
				11000 11000 11000 11000 11000 11000 11000 11000 11000 11000 11000 11000 11000 11000 11000 11000 11000 11000
				11000 11000 11000 11000 11000 11000 11000 11000 11000 11000 11000 11000 11000 11000 11000 11000 11000 11000
				11000 11000 11000 11000 11000 11000 11000 11000 11000 11000 11000 11000 11000 11000 11000 11000 11000 11000
				11000 11000 11000 11000 11000 11000 11000 11000 11000 11000 11000 11000 11000 11000 11000 11000 11000 11000
				11000 11000 11000 11000 11000 11000 11000 11000 11000 11000 11000 11000 11000 11000 11000 11000 11000 11000
				11000 11000 11000 11000 11000 11000 11000 11000 11000 11000 11000 11000 11000 11000 11000 11000 11000 11000
				11000 11000 11000 11000 11000 11000 11000 11000 11000 11000 11000 11000 11000 11000 11000 11000 11000 11000
				11000 11000 11000>;

			PS_Config_Lmt_Open_Rawdata_P = <
			    65535 3376 3371 3377 3383 3366 3368 3312 65535 65535 3377 3436 3440 3450 3449 3429 3432 65535
			    3060 3095 3101 3102 3106 3093 3098 3085 2920 2968 3137 3150 3149 3159 3160 3151 3146 3098 
			    3205 3175 3179 3180 3184 3172 3173 3158 3159 3214 3210 3224 3225 3236 3237 3224 3220 3234 
			    3137 3107 3111 3111 3115 3103 3106 3090 3091 3140 3137 3150 3151 3160 3163 3156 3151 3168 
			    3211 3181 3188 3188 3189 3177 3181 3164 3164 3220 3215 3229 3232 3241 3244 3237 3233 3249 
			    3143 3114 3119 3116 3119 3108 3111 3094 3097 3141 3136 3150 3153 3160 3163 3159 3156 3175 
			    3215 3185 3190 3189 3193 3181 3182 3166 3169 3218 3210 3228 3229 3238 3241 3237 3232 3249 
			    3140 3111 3116 3114 3117 3107 3108 3091 3097 3138 3132 3147 3149 3156 3160 3160 3155 3175 
			    3212 3182 3189 3185 3190 3179 3180 3162 3168 3215 3207 3224 3224 3233 3237 3237 3232 3253 
			    3136 3106 3111 3108 3112 3102 3103 3088 3091 3140 3132 3149 3149 3156 3159 3162 3158 3180 
			    3212 3181 3189 3185 3188 3177 3179 3164 3168 3212 3203 3216 3219 3228 3229 3233 3228 3249 
			    3132 3101 3107 3103 3106 3094 3097 3084 3088 3130 3120 3132 3133 3141 3143 3149 3145 3168 
			    3202 3172 3180 3175 3179 3167 3169 3155 3159 3201 3190 3201 3202 3211 3214 3221 3220 3242 
			    3125 3095 3102 3098 3102 3091 3093 3082 3082 3123 3115 3123 3123 3133 3134 3143 3142 3166 
			    3193 3162 3172 3167 3169 3159 3163 3155 3151 3193 3185 3194 3193 3203 3205 3214 3210 3236 
			    3111 3081 3091 3085 3089 3078 3085 3075 3072 3106 3099 3107 3106 3115 3117 3125 3124 3150 
			    3176 3146 3156 3151 3154 3143 3149 3145 3137 3182 3177 3180 3180 3189 3190 3199 3199 3227 
			    3094 3065 3076 3071 3072 3062 3068 3060 3056 3098 3089 3097 3094 3104 3106 3115 3116 3140 
			    3160 3130 3140 3134 3138 3127 3133 3125 3123 3162 3154 3162 3158 3168 3171 3180 3181 3206 
			    3080 3049 3059 3054 3058 3046 3054 3045 3047 3081 3073 3081 3076 3085 3088 3097 3095 3124 
			    3141 3110 3120 3115 3119 3108 3115 3106 3108 3151 3143 3151 3146 3156 3159 3167 3167 3197 
			    3059 3025 3034 3032 3034 3024 3033 3023 3024 3060 3051 3060 3055 3064 3067 3073 3076 3104 
			    3119 3086 3094 3091 3094 3085 3091 3082 3084 3127 3119 3127 3121 3132 3134 3141 3143 3172 
			    3034 3002 3010 3006 3010 3000 3008 2999 3000 3034 3026 3036 3029 3038 3039 3047 3050 3078 
			    2899 2870 2881 2880 2881 2870 2878 2869 2876 2911 2899 2907 2902 2911 2915 2920 2924 2948 
			    2817 2789 2798 2795 2798 2789 2796 2787 2792 2824 2812 2821 2816 2824 2826 2833 2837 2861 
			    2878 2846 2855 2852 2855 2846 2854 2847 2851 2889 2881 2887 2882 2890 2893 2899 2903 2932 
			    2794 2761 2770 2766 2769 2763 2769 2763 2765 2787 2783 2794 2790 2796 2798 2804 2807 2835 
			    2851 2821 2829 2825 2828 2821 2829 2818 2824 2851 2846 2857 2852 2859 2860 2868 2870 2898 
			    2764 2734 2742 2738 2740 2733 2742 2730 2735 2760 2755 2766 2760 2766 2768 2776 2777 2802 
			    2816 2786 2792 2789 2791 2783 2792 2781 2787 2821 2816 2828 2821 2828 2829 2835 2838 2863 
			    2731 2701 2708 2704 2707 2700 2709 2698 2703 2726 2722 2735 2727 2734 2735 2743 2743 2769 
			    2783 2755 2761 2757 2760 2752 2764 2750 2756 2785 2779 2792 2783 2791 2792 2799 2800 2828 
			    2340 2668 2674 2670 2674 2665 2678 2662 2670 2692 2687 2703 2692 2699 2700 2708 2708 2371 
			    2310 2712 2718 2714 2718 2709 2724 2705 2714 2753 2748 2765 2753 2761 2761 2768 2769 2357 
			    2158 2565 2677 2686 2686 2666 2679 2662 2673 2701 2694 2711 2699 2720 2724 2717 2610 2193 
			    4096 4096 4096>;

			PS_Config_Lmt_Open_Rawdata_N = <
			    (-65535) 1818 1815 1819 1821 1812 1814 1784 (-65535) (-65535) 1819 1850 1852 1858 1857 1847 1848 (-65535)
			    1648 1667 1670 1670 1672 1665 1668 1661 1572 1598 1689 1696 1695 1701 1702 1697 1694 1668        
			    1726 1709 1712 1712 1714 1708 1709 1700 1701 1730 1728 1736 1737 1742 1743 1736 1734 1742        
			    1689 1673 1675 1675 1677 1671 1672 1664 1665 1691 1689 1696 1697 1702 1703 1700 1697 1706        
			    1729 1713 1716 1716 1717 1711 1713 1704 1704 1734 1731 1739 1740 1745 1747 1743 1741 1749        
			    1693 1677 1679 1678 1679 1674 1675 1666 1667 1691 1688 1696 1698 1702 1703 1701 1700 1709        
			    1731 1715 1718 1717 1719 1713 1714 1705 1707 1733 1728 1738 1739 1744 1745 1743 1740 1749        
			    1691 1675 1678 1677 1679 1673 1674 1665 1667 1690 1686 1695 1695 1700 1702 1702 1699 1709        
			    1730 1714 1717 1715 1718 1712 1712 1702 1706 1731 1727 1736 1736 1741 1743 1743 1740 1751        
			    1688 1672 1675 1674 1676 1670 1671 1663 1665 1691 1686 1695 1695 1700 1701 1702 1700 1712        
			    1730 1713 1717 1715 1716 1711 1712 1704 1706 1730 1725 1732 1733 1738 1739 1741 1738 1749        
			    1686 1670 1673 1671 1672 1666 1667 1660 1663 1686 1680 1686 1687 1691 1693 1695 1693 1706        
			    1724 1708 1712 1709 1712 1705 1707 1699 1701 1723 1718 1723 1724 1729 1730 1735 1734 1746        
			    1683 1667 1670 1668 1670 1665 1665 1660 1660 1681 1677 1681 1681 1687 1688 1693 1692 1705        
			    1719 1702 1708 1705 1707 1701 1703 1699 1697 1719 1715 1720 1719 1725 1726 1730 1728 1742        
			    1675 1659 1665 1661 1663 1658 1661 1656 1654 1672 1669 1673 1672 1677 1679 1683 1682 1696        
			    1710 1694 1700 1697 1698 1693 1695 1693 1689 1714 1711 1712 1712 1717 1718 1723 1723 1737        
			    1666 1651 1656 1653 1654 1649 1652 1648 1646 1668 1663 1667 1666 1672 1672 1677 1678 1691        
			    1702 1686 1691 1688 1690 1684 1687 1683 1681 1702 1698 1702 1700 1706 1707 1712 1713 1726        
			    1658 1642 1647 1644 1646 1640 1644 1639 1641 1659 1655 1659 1656 1661 1663 1667 1667 1682        
			    1691 1674 1680 1677 1679 1674 1677 1672 1674 1697 1693 1697 1694 1700 1701 1705 1705 1721        
			    1647 1629 1634 1632 1634 1628 1633 1628 1628 1648 1643 1648 1645 1650 1651 1655 1656 1672        
			    1679 1662 1666 1665 1666 1661 1665 1660 1660 1684 1679 1684 1681 1686 1688 1691 1693 1708        
			    1634 1616 1621 1618 1621 1616 1620 1615 1616 1634 1630 1635 1631 1636 1637 1641 1642 1658        
			    1561 1546 1551 1551 1551 1546 1550 1545 1548 1567 1561 1565 1562 1567 1569 1572 1574 1588        
			    1517 1502 1506 1505 1506 1502 1506 1501 1504 1520 1514 1519 1516 1520 1522 1525 1527 1541        
			    1550 1532 1537 1536 1537 1532 1537 1533 1535 1555 1551 1555 1552 1556 1558 1561 1563 1579        
			    1504 1487 1492 1490 1491 1488 1491 1488 1489 1501 1499 1504 1502 1506 1506 1510 1511 1527        
			    1535 1519 1523 1521 1523 1519 1523 1518 1520 1535 1532 1539 1536 1539 1540 1544 1546 1560        
			    1488 1472 1476 1474 1476 1471 1476 1470 1473 1486 1483 1490 1486 1490 1490 1495 1495 1509        
			    1516 1500 1504 1502 1503 1499 1504 1497 1501 1519 1516 1523 1519 1523 1523 1527 1528 1541        
			    1471 1455 1458 1456 1457 1454 1459 1453 1455 1468 1466 1473 1469 1472 1473 1477 1477 1491        
			    1499 1483 1487 1485 1486 1482 1488 1481 1484 1499 1497 1504 1499 1503 1504 1507 1508 1523        
			    1260 1436 1440 1438 1440 1435 1442 1434 1438 1450 1447 1455 1450 1453 1454 1458 1458 1277        
			    1244 1460 1464 1462 1464 1459 1467 1457 1462 1483 1480 1489 1483 1487 1487 1490 1491 1269        
			    1162 1381 1441 1446 1446 1436 1443 1434 1439 1455 1450 1460 1453 1464 1467 1463 1406 1181        
				50 50 50>;

			PS_Config_Lmt_FW_Rawdata_P = <
			    65535 2160 2160 2160 2160 2160 2160 2160 65535 65535 2160 2160 2160 2160 2160 2160 2160 65535
			    2160 2160 2160 2160 2160 2160 2160 2160 2160 2160 2160 2160 2160 2160 2160 2160 2160 2160 
			    2160 2160 2160 2160 2160 2160 2160 2160 2160 2160 2160 2160 2160 2160 2160 2160 2160 2160 
			    2160 2160 2160 2160 2160 2160 2160 2160 2160 2160 2160 2160 2160 2160 2160 2160 2160 2160 
			    2160 2160 2160 2160 2160 2160 2160 2160 2160 2160 2160 2160 2160 2160 2160 2160 2160 2160 
			    2160 2160 2160 2160 2160 2160 2160 2160 2160 2160 2160 2160 2160 2160 2160 2160 2160 2160 
			    2160 2160 2160 2160 2160 2160 2160 2160 2160 2160 2160 2160 2160 2160 2160 2160 2160 2160 
			    2160 2160 2160 2160 2160 2160 2160 2160 2160 2160 2160 2160 2160 2160 2160 2160 2160 2160 
			    2160 2160 2160 2160 2160 2160 2160 2160 2160 2160 2160 2160 2160 2160 2160 2160 2160 2160 
			    2160 2160 2160 2160 2160 2160 2160 2160 2160 2160 2160 2160 2160 2160 2160 2160 2160 2160 
			    2160 2160 2160 2160 2160 2160 2160 2160 2160 2160 2160 2160 2160 2160 2160 2160 2160 2160 
			    2160 2160 2160 2160 2160 2160 2160 2160 2160 2160 2160 2160 2160 2160 2160 2160 2160 2160 
			    2160 2160 2160 2160 2160 2160 2160 2160 2160 2160 2160 2160 2160 2160 2160 2160 2160 2160 
			    2160 2160 2160 2160 2160 2160 2160 2160 2160 2160 2160 2160 2160 2160 2160 2160 2160 2160 
			    2160 2160 2160 2160 2160 2160 2160 2160 2160 2160 2160 2160 2160 2160 2160 2160 2160 2160 
			    2160 2160 2160 2160 2160 2160 2160 2160 2160 2160 2160 2160 2160 2160 2160 2160 2160 2160 
			    2160 2160 2160 2160 2160 2160 2160 2160 2160 2160 2160 2160 2160 2160 2160 2160 2160 2160 
			    2160 2160 2160 2160 2160 2160 2160 2160 2160 2160 2160 2160 2160 2160 2160 2160 2160 2160 
			    2160 2160 2160 2160 2160 2160 2160 2160 2160 2160 2160 2160 2160 2160 2160 2160 2160 2160 
			    2160 2160 2160 2160 2160 2160 2160 2160 2160 2160 2160 2160 2160 2160 2160 2160 2160 2160 
			    2160 2160 2160 2160 2160 2160 2160 2160 2160 2160 2160 2160 2160 2160 2160 2160 2160 2160 
			    2160 2160 2160 2160 2160 2160 2160 2160 2160 2160 2160 2160 2160 2160 2160 2160 2160 2160 
			    2160 2160 2160 2160 2160 2160 2160 2160 2160 2160 2160 2160 2160 2160 2160 2160 2160 2160 
			    2160 2160 2160 2160 2160 2160 2160 2160 2160 2160 2160 2160 2160 2160 2160 2160 2160 2160 
			    2160 2160 2160 2160 2160 2160 2160 2160 2160 2160 2160 2160 2160 2160 2160 2160 2160 2160 
			    2160 2160 2160 2160 2160 2160 2160 2160 2160 2160 2160 2160 2160 2160 2160 2160 2160 2160 
			    2160 2160 2160 2160 2160 2160 2160 2160 2160 2160 2160 2160 2160 2160 2160 2160 2160 2160 
			    2160 2160 2160 2160 2160 2160 2160 2160 2160 2160 2160 2160 2160 2160 2160 2160 2160 2160 
			    2160 2160 2160 2160 2160 2160 2160 2160 2160 2160 2160 2160 2160 2160 2160 2160 2160 2160 
			    2160 2160 2160 2160 2160 2160 2160 2160 2160 2160 2160 2160 2160 2160 2160 2160 2160 2160 
			    2160 2160 2160 2160 2160 2160 2160 2160 2160 2160 2160 2160 2160 2160 2160 2160 2160 2160 
			    2160 2160 2160 2160 2160 2160 2160 2160 2160 2160 2160 2160 2160 2160 2160 2160 2160 2160 
			    2160 2160 2160 2160 2160 2160 2160 2160 2160 2160 2160 2160 2160 2160 2160 2160 2160 2160 
			    2160 2160 2160 2160 2160 2160 2160 2160 2160 2160 2160 2160 2160 2160 2160 2160 2160 2160 
			    2160 2160 2160 2160 2160 2160 2160 2160 2160 2160 2160 2160 2160 2160 2160 2160 2160 2160 
			    2160 2160 2160 2160 2160 2160 2160 2160 2160 2160 2160 2160 2160 2160 2160 2160 2160 2160 
				1920 1920 1920>;

			PS_Config_Lmt_FW_Rawdata_N = <
			    (-65535) 1040 1040 1040 1040 1040 1040 1040 (-65535) (-65535) 1040 1040 1040 1040 1040 1040 1040 (-65535)
			    1040 1040 1040 1040 1040 1040 1040 1040 1040 1040 1040 1040 1040 1040 1040 1040 1040 1040        
			    1040 1040 1040 1040 1040 1040 1040 1040 1040 1040 1040 1040 1040 1040 1040 1040 1040 1040        
			    1040 1040 1040 1040 1040 1040 1040 1040 1040 1040 1040 1040 1040 1040 1040 1040 1040 1040        
			    1040 1040 1040 1040 1040 1040 1040 1040 1040 1040 1040 1040 1040 1040 1040 1040 1040 1040        
			    1040 1040 1040 1040 1040 1040 1040 1040 1040 1040 1040 1040 1040 1040 1040 1040 1040 1040        
			    1040 1040 1040 1040 1040 1040 1040 1040 1040 1040 1040 1040 1040 1040 1040 1040 1040 1040        
			    1040 1040 1040 1040 1040 1040 1040 1040 1040 1040 1040 1040 1040 1040 1040 1040 1040 1040        
			    1040 1040 1040 1040 1040 1040 1040 1040 1040 1040 1040 1040 1040 1040 1040 1040 1040 1040        
			    1040 1040 1040 1040 1040 1040 1040 1040 1040 1040 1040 1040 1040 1040 1040 1040 1040 1040        
			    1040 1040 1040 1040 1040 1040 1040 1040 1040 1040 1040 1040 1040 1040 1040 1040 1040 1040        
			    1040 1040 1040 1040 1040 1040 1040 1040 1040 1040 1040 1040 1040 1040 1040 1040 1040 1040        
			    1040 1040 1040 1040 1040 1040 1040 1040 1040 1040 1040 1040 1040 1040 1040 1040 1040 1040        
			    1040 1040 1040 1040 1040 1040 1040 1040 1040 1040 1040 1040 1040 1040 1040 1040 1040 1040        
			    1040 1040 1040 1040 1040 1040 1040 1040 1040 1040 1040 1040 1040 1040 1040 1040 1040 1040        
			    1040 1040 1040 1040 1040 1040 1040 1040 1040 1040 1040 1040 1040 1040 1040 1040 1040 1040        
			    1040 1040 1040 1040 1040 1040 1040 1040 1040 1040 1040 1040 1040 1040 1040 1040 1040 1040        
			    1040 1040 1040 1040 1040 1040 1040 1040 1040 1040 1040 1040 1040 1040 1040 1040 1040 1040        
			    1040 1040 1040 1040 1040 1040 1040 1040 1040 1040 1040 1040 1040 1040 1040 1040 1040 1040        
			    1040 1040 1040 1040 1040 1040 1040 1040 1040 1040 1040 1040 1040 1040 1040 1040 1040 1040        
			    1040 1040 1040 1040 1040 1040 1040 1040 1040 1040 1040 1040 1040 1040 1040 1040 1040 1040        
			    1040 1040 1040 1040 1040 1040 1040 1040 1040 1040 1040 1040 1040 1040 1040 1040 1040 1040        
			    1040 1040 1040 1040 1040 1040 1040 1040 1040 1040 1040 1040 1040 1040 1040 1040 1040 1040        
			    1040 1040 1040 1040 1040 1040 1040 1040 1040 1040 1040 1040 1040 1040 1040 1040 1040 1040        
			    1040 1040 1040 1040 1040 1040 1040 1040 1040 1040 1040 1040 1040 1040 1040 1040 1040 1040        
			    1040 1040 1040 1040 1040 1040 1040 1040 1040 1040 1040 1040 1040 1040 1040 1040 1040 1040        
			    1040 1040 1040 1040 1040 1040 1040 1040 1040 1040 1040 1040 1040 1040 1040 1040 1040 1040        
			    1040 1040 1040 1040 1040 1040 1040 1040 1040 1040 1040 1040 1040 1040 1040 1040 1040 1040        
			    1040 1040 1040 1040 1040 1040 1040 1040 1040 1040 1040 1040 1040 1040 1040 1040 1040 1040        
			    1040 1040 1040 1040 1040 1040 1040 1040 1040 1040 1040 1040 1040 1040 1040 1040 1040 1040        
			    1040 1040 1040 1040 1040 1040 1040 1040 1040 1040 1040 1040 1040 1040 1040 1040 1040 1040        
			    1040 1040 1040 1040 1040 1040 1040 1040 1040 1040 1040 1040 1040 1040 1040 1040 1040 1040        
			    1040 1040 1040 1040 1040 1040 1040 1040 1040 1040 1040 1040 1040 1040 1040 1040 1040 1040        
			    1040 1040 1040 1040 1040 1040 1040 1040 1040 1040 1040 1040 1040 1040 1040 1040 1040 1040        
			    1040 1040 1040 1040 1040 1040 1040 1040 1040 1040 1040 1040 1040 1040 1040 1040 1040 1040        
			    1040 1040 1040 1040 1040 1040 1040 1040 1040 1040 1040 1040 1040 1040 1040 1040 1040 1040        
				240 240 240>;

			PS_Config_Lmt_FW_CC_P = <
			    65535 129 127 126 127 127 126 130 65535 65535 134 130 131 131 130 130 133 65535
			    121 118 116 116 116 117 116 117 117 118 118 117 117 117 117 117 118 121        
			    120 116 116 116 116 116 114 116 116 121 121 120 120 120 120 120 121 124        
			    120 117 116 116 116 116 116 116 117 120 118 118 118 117 117 118 118 121        
			    120 116 116 116 116 116 116 116 116 121 120 118 118 118 118 118 120 122        
			    121 118 117 117 117 117 117 118 118 118 118 117 117 117 117 117 118 121        
			    118 116 116 116 114 116 116 116 116 122 121 120 121 120 120 120 121 124        
			    120 116 116 116 116 116 116 117 117 120 118 117 118 117 117 117 118 121        
			    118 116 116 116 116 116 116 116 116 121 120 118 118 118 118 118 118 122        
			    121 117 117 117 117 117 117 118 118 121 118 117 117 117 117 117 117 121        
			    118 116 114 114 114 116 116 116 116 124 121 120 120 118 118 118 120 122        
			    118 116 116 116 116 116 116 117 117 122 118 117 118 117 117 117 117 120        
			    118 116 116 116 116 116 116 117 116 124 121 118 118 118 117 117 118 121        
			    120 117 116 117 117 118 117 120 118 122 120 116 117 116 116 116 116 118        
			    117 114 114 114 114 116 116 118 116 126 121 120 120 118 118 118 118 121        
			    118 116 116 116 116 116 116 120 117 124 121 117 117 116 116 116 116 118        
			    118 116 116 116 116 116 116 118 117 125 121 118 118 117 117 117 117 120        
			    118 116 117 117 117 118 117 118 118 122 118 116 116 116 116 116 116 118        
			    117 114 114 114 114 116 116 117 116 126 121 118 118 118 118 118 118 121        
			    118 116 116 116 116 116 116 118 120 124 118 117 117 116 116 116 116 118        
			    118 116 116 116 116 116 116 117 117 125 118 118 118 117 117 117 117 118        
			    118 116 117 117 117 118 118 118 118 122 117 116 116 116 116 116 114 117        
			    117 114 114 116 116 116 116 117 116 126 120 118 118 118 118 117 117 120        
			    118 116 116 116 116 117 117 118 117 124 117 116 117 116 116 116 116 117        
			    116 114 114 114 114 116 116 117 116 122 118 116 116 114 114 114 114 117        
			    118 116 116 116 116 118 117 118 117 121 117 116 116 113 113 113 113 116        
			    116 113 113 114 114 116 116 117 116 120 120 118 118 116 116 116 116 118        
			    117 116 116 116 116 116 116 118 116 116 118 116 116 114 114 114 113 116        
			    117 114 114 116 116 116 116 118 116 116 118 116 117 116 116 116 116 117        
			    118 116 116 116 116 118 117 118 117 114 116 114 114 113 113 113 113 116        
			    116 114 113 114 114 116 114 117 114 117 120 117 117 116 116 116 116 118        
			    117 114 116 116 116 116 116 118 116 114 117 114 116 113 113 113 113 116        
			    116 114 114 114 116 116 116 118 116 116 118 116 116 114 114 114 114 116        
			    116 116 116 116 116 117 118 120 116 113 117 114 113 113 113 113 112 112        
			    113 113 113 113 113 116 116 117 114 116 120 118 116 116 116 116 116 114        
			    122 125 126 126 125 126 127 129 129 129 129 126 125 124 124 124 124 121        
				314 314 314>;

			PS_Config_Lmt_FW_CC_N = <
			    (-65535) 69 69 68 69 69 68 70 (-65535) (-65535) 72 70 71 71 70 70 71 (-65535)
			    65 64 62 62 62 63 62 63 63 64 64 63 63 63 63 63 64 65                
			    64 62 62 62 62 62 62 62 62 65 65 64 64 64 64 64 65 67                
			    64 63 62 62 62 62 62 62 63 64 64 64 64 63 63 64 64 65                
			    64 62 62 62 62 62 62 62 62 65 64 64 64 64 64 64 64 66                
			    65 64 63 63 63 63 63 64 64 64 64 63 63 63 63 63 64 65                
			    64 62 62 62 62 62 62 62 62 66 65 64 65 64 64 64 65 67                
			    64 62 62 62 62 62 62 63 63 64 64 63 64 63 63 63 64 65                
			    64 62 62 62 62 62 62 62 62 65 64 64 64 64 64 64 64 66                
			    65 63 63 63 63 63 63 64 64 65 64 63 63 63 63 63 63 65                
			    64 62 62 62 62 62 62 62 62 67 65 64 64 64 64 64 64 66                
			    64 62 62 62 62 62 62 63 63 66 64 63 64 63 63 63 63 64                
			    64 62 62 62 62 62 62 63 62 67 65 64 64 64 63 63 64 65                
			    64 63 62 63 63 64 63 64 64 66 64 62 63 62 62 62 62 64                
			    63 62 62 62 62 62 62 64 62 68 65 64 64 64 64 64 64 65                
			    64 62 62 62 62 62 62 64 63 67 65 63 63 62 62 62 62 64                
			    64 62 62 62 62 62 62 64 63 67 65 64 64 63 63 63 63 64                
			    64 62 63 63 63 64 63 64 64 66 64 62 62 62 62 62 62 64                
			    63 62 62 62 62 62 62 63 62 68 65 64 64 64 64 64 64 65                
			    64 62 62 62 62 62 62 64 64 67 64 63 63 62 62 62 62 64                
			    64 62 62 62 62 62 62 63 63 67 64 64 64 63 63 63 63 64                
			    64 62 63 63 63 64 64 64 64 66 63 62 62 62 62 62 62 63                
			    63 62 62 62 62 62 62 63 62 68 64 64 64 64 64 63 63 64                
			    64 62 62 62 62 63 63 64 63 67 63 62 63 62 62 62 62 63                
			    62 62 62 62 62 62 62 63 62 66 64 62 62 62 62 62 62 63                
			    64 62 62 62 62 64 63 64 63 65 63 62 62 61 61 61 61 62                
			    62 61 61 62 62 62 62 63 62 64 64 64 64 62 62 62 62 64                
			    63 62 62 62 62 62 62 64 62 62 64 62 62 62 62 62 61 62                
			    63 62 62 62 62 62 62 64 62 62 64 62 63 62 62 62 62 63                
			    64 62 62 62 62 64 63 64 63 62 62 62 62 61 61 61 61 62                
			    62 62 61 62 62 62 62 63 62 63 64 63 63 62 62 62 62 64                
			    63 62 62 62 62 62 62 64 62 62 63 62 62 61 61 61 61 62                
			    62 62 62 62 62 62 62 64 62 62 64 62 62 62 62 62 62 62                
			    62 62 62 62 62 63 64 64 62 61 63 62 61 61 61 61 60 60                
			    61 61 61 61 61 62 62 63 62 62 64 64 62 62 62 62 62 62                
			    66 67 68 68 67 68 69 69 69 69 69 68 67 67 67 67 67 65                
				30 30 30>;

			PS_Config_Lmt_FW_Diff_P = <
			    65535 50 50 50 50 50 50 50 65535 65535 50 50 50 50 50 50 50 65535
			    50 50 50 50 50 50 50 50 50 50 50 50 50 50 50 50 50 50    
			    50 50 50 50 50 50 50 50 50 50 50 50 50 50 50 50 50 50    
			    50 50 50 50 50 50 50 50 50 50 50 50 50 50 50 50 50 50    
			    50 50 50 50 50 50 50 50 50 50 50 50 50 50 50 50 50 50    
			    50 50 50 50 50 50 50 50 50 50 50 50 50 50 50 50 50 50    
			    50 50 50 50 50 50 50 50 50 50 50 50 50 50 50 50 50 50    
			    50 50 50 50 50 50 50 50 50 50 50 50 50 50 50 50 50 50    
			    50 50 50 50 50 50 50 50 50 50 50 50 50 50 50 50 50 50    
			    50 50 50 50 50 50 50 50 50 50 50 50 50 50 50 50 50 50    
			    50 50 50 50 50 50 50 50 50 50 50 50 50 50 50 50 50 50    
			    50 50 50 50 50 50 50 50 50 50 50 50 50 50 50 50 50 50    
			    50 50 50 50 50 50 50 50 50 50 50 50 50 50 50 50 50 50    
			    50 50 50 50 50 50 50 50 50 50 50 50 50 50 50 50 50 50    
			    50 50 50 50 50 50 50 50 50 50 50 50 50 50 50 50 50 50    
			    50 50 50 50 50 50 50 50 50 50 50 50 50 50 50 50 50 50    
			    50 50 50 50 50 50 50 50 50 50 50 50 50 50 50 50 50 50    
			    50 50 50 50 50 50 50 50 50 50 50 50 50 50 50 50 50 50    
			    50 50 50 50 50 50 50 50 50 50 50 50 50 50 50 50 50 50    
			    50 50 50 50 50 50 50 50 50 50 50 50 50 50 50 50 50 50    
			    50 50 50 50 50 50 50 50 50 50 50 50 50 50 50 50 50 50    
			    50 50 50 50 50 50 50 50 50 50 50 50 50 50 50 50 50 50    
			    50 50 50 50 50 50 50 50 50 50 50 50 50 50 50 50 50 50    
			    50 50 50 50 50 50 50 50 50 50 50 50 50 50 50 50 50 50    
			    50 50 50 50 50 50 50 50 50 50 50 50 50 50 50 50 50 50    
			    50 50 50 50 50 50 50 50 50 50 50 50 50 50 50 50 50 50    
			    50 50 50 50 50 50 50 50 50 50 50 50 50 50 50 50 50 50    
			    50 50 50 50 50 50 50 50 50 50 50 50 50 50 50 50 50 50    
			    50 50 50 50 50 50 50 50 50 50 50 50 50 50 50 50 50 50    
			    50 50 50 50 50 50 50 50 50 50 50 50 50 50 50 50 50 50    
			    50 50 50 50 50 50 50 50 50 50 50 50 50 50 50 50 50 50    
			    50 50 50 50 50 50 50 50 50 50 50 50 50 50 50 50 50 50    
			    50 50 50 50 50 50 50 50 50 50 50 50 50 50 50 50 50 50    
			    50 50 50 50 50 50 50 50 50 50 50 50 50 50 50 50 50 50    
			    50 50 50 50 50 50 50 50 50 50 50 50 50 50 50 50 50 50    
			    50 50 50 50 50 50 50 50 50 50 50 50 50 50 50 50 50 50    
				75 75 75>;

			PS_Config_Lmt_FW_Diff_N = <
			    (-65535) (-50) (-50) (-50) (-50) (-50) (-50) (-50) (-65535) (-65535) (-50) (-50) (-50) (-50) (-50) (-50) (-50) (-65535)
			    (-50) (-50) (-50) (-50) (-50) (-50) (-50) (-50) (-50) (-50) (-50) (-50) (-50) (-50) (-50) (-50) (-50) (-50)        
			    (-50) (-50) (-50) (-50) (-50) (-50) (-50) (-50) (-50) (-50) (-50) (-50) (-50) (-50) (-50) (-50) (-50) (-50)        
			    (-50) (-50) (-50) (-50) (-50) (-50) (-50) (-50) (-50) (-50) (-50) (-50) (-50) (-50) (-50) (-50) (-50) (-50)        
			    (-50) (-50) (-50) (-50) (-50) (-50) (-50) (-50) (-50) (-50) (-50) (-50) (-50) (-50) (-50) (-50) (-50) (-50)        
			    (-50) (-50) (-50) (-50) (-50) (-50) (-50) (-50) (-50) (-50) (-50) (-50) (-50) (-50) (-50) (-50) (-50) (-50)        
			    (-50) (-50) (-50) (-50) (-50) (-50) (-50) (-50) (-50) (-50) (-50) (-50) (-50) (-50) (-50) (-50) (-50) (-50)        
			    (-50) (-50) (-50) (-50) (-50) (-50) (-50) (-50) (-50) (-50) (-50) (-50) (-50) (-50) (-50) (-50) (-50) (-50)        
			    (-50) (-50) (-50) (-50) (-50) (-50) (-50) (-50) (-50) (-50) (-50) (-50) (-50) (-50) (-50) (-50) (-50) (-50)        
			    (-50) (-50) (-50) (-50) (-50) (-50) (-50) (-50) (-50) (-50) (-50) (-50) (-50) (-50) (-50) (-50) (-50) (-50)        
			    (-50) (-50) (-50) (-50) (-50) (-50) (-50) (-50) (-50) (-50) (-50) (-50) (-50) (-50) (-50) (-50) (-50) (-50)        
			    (-50) (-50) (-50) (-50) (-50) (-50) (-50) (-50) (-50) (-50) (-50) (-50) (-50) (-50) (-50) (-50) (-50) (-50)        
			    (-50) (-50) (-50) (-50) (-50) (-50) (-50) (-50) (-50) (-50) (-50) (-50) (-50) (-50) (-50) (-50) (-50) (-50)        
			    (-50) (-50) (-50) (-50) (-50) (-50) (-50) (-50) (-50) (-50) (-50) (-50) (-50) (-50) (-50) (-50) (-50) (-50)        
			    (-50) (-50) (-50) (-50) (-50) (-50) (-50) (-50) (-50) (-50) (-50) (-50) (-50) (-50) (-50) (-50) (-50) (-50)        
			    (-50) (-50) (-50) (-50) (-50) (-50) (-50) (-50) (-50) (-50) (-50) (-50) (-50) (-50) (-50) (-50) (-50) (-50)        
			    (-50) (-50) (-50) (-50) (-50) (-50) (-50) (-50) (-50) (-50) (-50) (-50) (-50) (-50) (-50) (-50) (-50) (-50)        
			    (-50) (-50) (-50) (-50) (-50) (-50) (-50) (-50) (-50) (-50) (-50) (-50) (-50) (-50) (-50) (-50) (-50) (-50)        
			    (-50) (-50) (-50) (-50) (-50) (-50) (-50) (-50) (-50) (-50) (-50) (-50) (-50) (-50) (-50) (-50) (-50) (-50)        
			    (-50) (-50) (-50) (-50) (-50) (-50) (-50) (-50) (-50) (-50) (-50) (-50) (-50) (-50) (-50) (-50) (-50) (-50)        
			    (-50) (-50) (-50) (-50) (-50) (-50) (-50) (-50) (-50) (-50) (-50) (-50) (-50) (-50) (-50) (-50) (-50) (-50)        
			    (-50) (-50) (-50) (-50) (-50) (-50) (-50) (-50) (-50) (-50) (-50) (-50) (-50) (-50) (-50) (-50) (-50) (-50)        
			    (-50) (-50) (-50) (-50) (-50) (-50) (-50) (-50) (-50) (-50) (-50) (-50) (-50) (-50) (-50) (-50) (-50) (-50)        
			    (-50) (-50) (-50) (-50) (-50) (-50) (-50) (-50) (-50) (-50) (-50) (-50) (-50) (-50) (-50) (-50) (-50) (-50)        
			    (-50) (-50) (-50) (-50) (-50) (-50) (-50) (-50) (-50) (-50) (-50) (-50) (-50) (-50) (-50) (-50) (-50) (-50)        
			    (-50) (-50) (-50) (-50) (-50) (-50) (-50) (-50) (-50) (-50) (-50) (-50) (-50) (-50) (-50) (-50) (-50) (-50)        
			    (-50) (-50) (-50) (-50) (-50) (-50) (-50) (-50) (-50) (-50) (-50) (-50) (-50) (-50) (-50) (-50) (-50) (-50)        
			    (-50) (-50) (-50) (-50) (-50) (-50) (-50) (-50) (-50) (-50) (-50) (-50) (-50) (-50) (-50) (-50) (-50) (-50)        
			    (-50) (-50) (-50) (-50) (-50) (-50) (-50) (-50) (-50) (-50) (-50) (-50) (-50) (-50) (-50) (-50) (-50) (-50)        
			    (-50) (-50) (-50) (-50) (-50) (-50) (-50) (-50) (-50) (-50) (-50) (-50) (-50) (-50) (-50) (-50) (-50) (-50)        
			    (-50) (-50) (-50) (-50) (-50) (-50) (-50) (-50) (-50) (-50) (-50) (-50) (-50) (-50) (-50) (-50) (-50) (-50)        
			    (-50) (-50) (-50) (-50) (-50) (-50) (-50) (-50) (-50) (-50) (-50) (-50) (-50) (-50) (-50) (-50) (-50) (-50)        
			    (-50) (-50) (-50) (-50) (-50) (-50) (-50) (-50) (-50) (-50) (-50) (-50) (-50) (-50) (-50) (-50) (-50) (-50)        
			    (-50) (-50) (-50) (-50) (-50) (-50) (-50) (-50) (-50) (-50) (-50) (-50) (-50) (-50) (-50) (-50) (-50) (-50)        
			    (-50) (-50) (-50) (-50) (-50) (-50) (-50) (-50) (-50) (-50) (-50) (-50) (-50) (-50) (-50) (-50) (-50) (-50)        
			    (-50) (-50) (-50) (-50) (-50) (-50) (-50) (-50) (-50) (-50) (-50) (-50) (-50) (-50) (-50) (-50) (-50) (-50)        
				(-75) (-75) (-75)>;

			PS_Config_Diff_Test_Frame = <50>;
		};/*}}}*/

		/* for Xiaomi C3X 672A TM 6.3" */
		novatek-mp-criteria-5929@0 {/*{{{*/
			#address-cells = <1>;
			#size-cells = <0>;
			compatible = "novatek-mp-criteria-5929";

			/* MP Config */
			IC_X_CFG_SIZE = <18>;
			IC_Y_CFG_SIZE = <36>;
			IC_KEY_CFG_SIZE = <4>;
			X_Channel = <18>;
			Y_Channel = <36>;
			AIN_X = <0 1 2 3 4 5 6 7 8 9 10 11 12 13 14 15 16 17>;
			AIN_Y = <0 1 2 3 4 5 6 7 8 9 10 11 12 13 14 15 16 17
						18 19 20 21 22 23 24 25 26 27 28 29 30 31 32 33 34 35>;
			AIN_KEY = <0 1 2 0xFF>;

			/* MP Criteria */
			PS_Config_Lmt_Short_Rawdata_P = <
				14000	14000	14000	14000	14000	14000	14000	14000	14000	14000	14000	14000	14000	14000	14000	14000	14000	14000
				14000	14000	14000	14000	14000	14000	14000	14000	14000	14000	14000	14000	14000	14000	14000	14000	14000	14000
				14000	14000	14000	14000	14000	14000	14000	14000	14000	14000	14000	14000	14000	14000	14000	14000	14000	14000
				14000	14000	14000	14000	14000	14000	14000	14000	14000	14000	14000	14000	14000	14000	14000	14000	14000	14000
				14000	14000	14000	14000	14000	14000	14000	14000	14000	14000	14000	14000	14000	14000	14000	14000	14000	14000
				14000	14000	14000	14000	14000	14000	14000	14000	14000	14000	14000	14000	14000	14000	14000	14000	14000	14000
				14000	14000	14000	14000	14000	14000	14000	14000	14000	14000	14000	14000	14000	14000	14000	14000	14000	14000
				14000	14000	14000	14000	14000	14000	14000	14000	14000	14000	14000	14000	14000	14000	14000	14000	14000	14000
				14000	14000	14000	14000	14000	14000	14000	14000	14000	14000	14000	14000	14000	14000	14000	14000	14000	14000
				14000	14000	14000	14000	14000	14000	14000	14000	14000	14000	14000	14000	14000	14000	14000	14000	14000	14000
				14000	14000	14000	14000	14000	14000	14000	14000	14000	14000	14000	14000	14000	14000	14000	14000	14000	14000
				14000	14000	14000	14000	14000	14000	14000	14000	14000	14000	14000	14000	14000	14000	14000	14000	14000	14000
				14000	14000	14000	14000	14000	14000	14000	14000	14000	14000	14000	14000	14000	14000	14000	14000	14000	14000
				14000	14000	14000	14000	14000	14000	14000	14000	14000	14000	14000	14000	14000	14000	14000	14000	14000	14000
				14000	14000	14000	14000	14000	14000	14000	14000	14000	14000	14000	14000	14000	14000	14000	14000	14000	14000
				14000	14000	14000	14000	14000	14000	14000	14000	14000	14000	14000	14000	14000	14000	14000	14000	14000	14000
				14000	14000	14000	14000	14000	14000	14000	14000	14000	14000	14000	14000	14000	14000	14000	14000	14000	14000
				14000	14000	14000	14000	14000	14000	14000	14000	14000	14000	14000	14000	14000	14000	14000	14000	14000	14000
				14000	14000	14000	14000	14000	14000	14000	14000	14000	14000	14000	14000	14000	14000	14000	14000	14000	14000
				14000	14000	14000	14000	14000	14000	14000	14000	14000	14000	14000	14000	14000	14000	14000	14000	14000	14000
				14000	14000	14000	14000	14000	14000	14000	14000	14000	14000	14000	14000	14000	14000	14000	14000	14000	14000
				14000	14000	14000	14000	14000	14000	14000	14000	14000	14000	14000	14000	14000	14000	14000	14000	14000	14000
				14000	14000	14000	14000	14000	14000	14000	14000	14000	14000	14000	14000	14000	14000	14000	14000	14000	14000
				14000	14000	14000	14000	14000	14000	14000	14000	14000	14000	14000	14000	14000	14000	14000	14000	14000	14000
				14000	14000	14000	14000	14000	14000	14000	14000	14000	14000	14000	14000	14000	14000	14000	14000	14000	14000
				14000	14000	14000	14000	14000	14000	14000	14000	14000	14000	14000	14000	14000	14000	14000	14000	14000	14000
				14000	14000	14000	14000	14000	14000	14000	14000	14000	14000	14000	14000	14000	14000	14000	14000	14000	14000
				14000	14000	14000	14000	14000	14000	14000	14000	14000	14000	14000	14000	14000	14000	14000	14000	14000	14000
				14000	14000	14000	14000	14000	14000	14000	14000	14000	14000	14000	14000	14000	14000	14000	14000	14000	14000
				14000	14000	14000	14000	14000	14000	14000	14000	14000	14000	14000	14000	14000	14000	14000	14000	14000	14000
				14000	14000	14000	14000	14000	14000	14000	14000	14000	14000	14000	14000	14000	14000	14000	14000	14000	14000
				14000	14000	14000	14000	14000	14000	14000	14000	14000	14000	14000	14000	14000	14000	14000	14000	14000	14000
				14000	14000	14000	14000	14000	14000	14000	14000	14000	14000	14000	14000	14000	14000	14000	14000	14000	14000
				14000	14000	14000	14000	14000	14000	14000	14000	14000	14000	14000	14000	14000	14000	14000	14000	14000	14000
				14000	14000	14000	14000	14000	14000	14000	14000	14000	14000	14000	14000	14000	14000	14000	14000	14000	14000
				14000	14000	14000	14000	14000	14000	14000	14000	14000	14000	14000	14000	14000	14000	14000	14000	14000	14000
				14000	14000	14000>;

			PS_Config_Lmt_Short_Rawdata_N = <
				11000	11000	11000	11000	11000	11000	11000	11000	11000	11000	11000	11000	11000	11000	11000	11000	11000	11000
				11000	11000	11000	11000	11000	11000	11000	11000	11000	11000	11000	11000	11000	11000	11000	11000	11000	11000
				11000	11000	11000	11000	11000	11000	11000	11000	11000	11000	11000	11000	11000	11000	11000	11000	11000	11000
				11000	11000	11000	11000	11000	11000	11000	11000	11000	11000	11000	11000	11000	11000	11000	11000	11000	11000
				11000	11000	11000	11000	11000	11000	11000	11000	11000	11000	11000	11000	11000	11000	11000	11000	11000	11000
				11000	11000	11000	11000	11000	11000	11000	11000	11000	11000	11000	11000	11000	11000	11000	11000	11000	11000
				11000	11000	11000	11000	11000	11000	11000	11000	11000	11000	11000	11000	11000	11000	11000	11000	11000	11000
				11000	11000	11000	11000	11000	11000	11000	11000	11000	11000	11000	11000	11000	11000	11000	11000	11000	11000
				11000	11000	11000	11000	11000	11000	11000	11000	11000	11000	11000	11000	11000	11000	11000	11000	11000	11000
				11000	11000	11000	11000	11000	11000	11000	11000	11000	11000	11000	11000	11000	11000	11000	11000	11000	11000
				11000	11000	11000	11000	11000	11000	11000	11000	11000	11000	11000	11000	11000	11000	11000	11000	11000	11000
				11000	11000	11000	11000	11000	11000	11000	11000	11000	11000	11000	11000	11000	11000	11000	11000	11000	11000
				11000	11000	11000	11000	11000	11000	11000	11000	11000	11000	11000	11000	11000	11000	11000	11000	11000	11000
				11000	11000	11000	11000	11000	11000	11000	11000	11000	11000	11000	11000	11000	11000	11000	11000	11000	11000
				11000	11000	11000	11000	11000	11000	11000	11000	11000	11000	11000	11000	11000	11000	11000	11000	11000	11000
				11000	11000	11000	11000	11000	11000	11000	11000	11000	11000	11000	11000	11000	11000	11000	11000	11000	11000
				11000	11000	11000	11000	11000	11000	11000	11000	11000	11000	11000	11000	11000	11000	11000	11000	11000	11000
				11000	11000	11000	11000	11000	11000	11000	11000	11000	11000	11000	11000	11000	11000	11000	11000	11000	11000
				11000	11000	11000	11000	11000	11000	11000	11000	11000	11000	11000	11000	11000	11000	11000	11000	11000	11000
				11000	11000	11000	11000	11000	11000	11000	11000	11000	11000	11000	11000	11000	11000	11000	11000	11000	11000
				11000	11000	11000	11000	11000	11000	11000	11000	11000	11000	11000	11000	11000	11000	11000	11000	11000	11000
				11000	11000	11000	11000	11000	11000	11000	11000	11000	11000	11000	11000	11000	11000	11000	11000	11000	11000
				11000	11000	11000	11000	11000	11000	11000	11000	11000	11000	11000	11000	11000	11000	11000	11000	11000	11000
				11000	11000	11000	11000	11000	11000	11000	11000	11000	11000	11000	11000	11000	11000	11000	11000	11000	11000
				11000	11000	11000	11000	11000	11000	11000	11000	11000	11000	11000	11000	11000	11000	11000	11000	11000	11000
				11000	11000	11000	11000	11000	11000	11000	11000	11000	11000	11000	11000	11000	11000	11000	11000	11000	11000
				11000	11000	11000	11000	11000	11000	11000	11000	11000	11000	11000	11000	11000	11000	11000	11000	11000	11000
				11000	11000	11000	11000	11000	11000	11000	11000	11000	11000	11000	11000	11000	11000	11000	11000	11000	11000
				11000	11000	11000	11000	11000	11000	11000	11000	11000	11000	11000	11000	11000	11000	11000	11000	11000	11000
				11000	11000	11000	11000	11000	11000	11000	11000	11000	11000	11000	11000	11000	11000	11000	11000	11000	11000
				11000	11000	11000	11000	11000	11000	11000	11000	11000	11000	11000	11000	11000	11000	11000	11000	11000	11000
				11000	11000	11000	11000	11000	11000	11000	11000	11000	11000	11000	11000	11000	11000	11000	11000	11000	11000
				11000	11000	11000	11000	11000	11000	11000	11000	11000	11000	11000	11000	11000	11000	11000	11000	11000	11000
				11000	11000	11000	11000	11000	11000	11000	11000	11000	11000	11000	11000	11000	11000	11000	11000	11000	11000
				11000	11000	11000	11000	11000	11000	11000	11000	11000	11000	11000	11000	11000	11000	11000	11000	11000	11000
				11000	11000	11000	11000	11000	11000	11000	11000	11000	11000	11000	11000	11000	11000	11000	11000	11000	11000
				11000	11000	11000>;

			PS_Config_Lmt_Open_Rawdata_P = <
				1921	2914	3032	3036	3040	3025	3031	2876	65535	65535	2882	3049	3041	3050	3060	3079	2959	1946
				2844	3007	3003	3006	3008	2997	3003	2984	2899	2940	3026	3046	3039	3045	3058	3075	3084	2887
				3053	3018	3014	3017	3018	3008	3014	2995	2979	3014	3027	3048	3042	3048	3063	3079	3086	3092
				3026	3022	3021	3023	3023	3013	3017	2997	2981	3023	3037	3056	3053	3058	3072	3086	3094	3096
				3034	3022	3023	3025	3023	3014	3018	2999	2983	3031	3044	3059	3058	3064	3075	3089	3098	3098
				3037	3036	3039	3037	3036	3027	3031	3011	2995	3034	3046	3060	3059	3067	3077	3089	3100	3097
				3037	3036	3036	3036	3035	3026	3028	3008	2998	3023	3039	3051	3053	3059	3070	3082	3091	3083
				3050	3031	3032	3030	3031	3022	3025	3002	2994	3042	3056	3060	3055	3072	3082	3089	3102	3093
				3049	3027	3030	3027	3028	3021	3023	3001	2994	3049	3061	3069	3063	3078	3089	3098	3105	3096
				3045	3032	3035	3031	3034	3025	3027	3007	2998	3042	3055	3063	3058	3072	3083	3091	3097	3084
				3039	3032	3036	3031	3031	3022	3023	3007	2995	3040	3049	3056	3053	3067	3077	3084	3091	3078
				3042	3022	3027	3022	3022	3013	3016	2998	2989	3040	3048	3055	3054	3068	3074	3082	3089	3075
				3040	3021	3026	3020	3022	3013	3014	2998	2989	3039	3048	3056	3053	3065	3073	3082	3084	3069
				3027	3027	3031	3023	3025	3016	3017	3006	2993	3045	3054	3063	3060	3074	3079	3087	3088	3074
				3026	3017	3027	3018	3021	3011	3016	3006	2990	3032	3040	3053	3049	3063	3068	3077	3075	3061
				3027	3020	3028	3021	3022	3014	3022	3012	2995	3034	3040	3049	3049	3063	3067	3075	3072	3056
				3022	3006	3014	3007	3008	2999	3008	3006	2981	3022	3028	3037	3039	3050	3053	3061	3060	3045
				3023	2994	3004	2997	2997	2988	2995	2990	2971	3022	3030	3037	3037	3049	3050	3060	3056	3046
				3007	2999	3004	2998	2998	2989	2994	2989	2965	3018	3026	3034	3034	3044	3046	3055	3048	3031
				2992	2989	2997	2989	2989	2979	2987	2981	2969	3008	3014	3025	3023	3032	3034	3044	3036	3025
				2997	2981	2988	2980	2979	2970	2978	2973	2961	3013	3017	3028	3026	3036	3036	3045	3041	3027
				2988	2979	2985	2978	2976	2969	2979	2970	2957	3006	3008	3021	3018	3027	3027	3035	3032	3018
				2980	2973	2978	2971	2969	2961	2971	2965	2951	3002	3004	3017	3014	3022	3023	3028	3023	3008
				2978	2962	2967	2960	2959	2951	2961	2955	2941	2990	2997	3008	3006	3013	3012	3018	3014	2998
				2713	2683	2691	2688	2684	2674	2680	2674	2668	2716	2716	2733	2730	2739	2741	2744	2740	2735
				2708	2696	2703	2700	2696	2687	2696	2688	2680	2716	2716	2731	2729	2738	2740	2743	2739	2736
				2687	2684	2689	2684	2683	2674	2683	2678	2670	2707	2708	2724	2721	2730	2734	2735	2734	2729
				2697	2683	2688	2683	2682	2677	2684	2678	2670	2694	2697	2711	2708	2716	2720	2721	2721	2715
				2686	2668	2673	2668	2667	2661	2669	2661	2654	2692	2694	2708	2706	2713	2716	2719	2719	2712
				2683	2663	2668	2663	2660	2655	2664	2655	2649	2684	2686	2697	2694	2703	2706	2710	2711	2706
				2668	2651	2654	2650	2649	2642	2651	2641	2636	2677	2679	2689	2687	2694	2697	2701	2702	2696
				2661	2642	2646	2641	2641	2636	2646	2635	2630	2668	2670	2682	2678	2687	2689	2692	2694	2688
				2650	2632	2635	2630	2631	2623	2636	2623	2618	2653	2655	2664	2661	2670	2672	2675	2678	2670
				2640	2617	2621	2617	2617	2611	2623	2609	2603	2665	2670	2677	2675	2684	2686	2691	2694	2697
				2393	2600	2603	2600	2600	2594	2608	2592	2586	2620	2626	2644	2632	2641	2640	2647	2653	2428
				1564	2505	2630	2630	2633	2626	2640	2622	2621	2642	2642	2663	2651	2661	2658	2664	2546	1601
				4096	4096	4096>;

			PS_Config_Lmt_Open_Rawdata_N = <
				1104	1675	1743	1745	1747	1738	1742	1653	(-65535)	(-65535)	1657	1752	1748	1753	1759	1770	1700	1119
				1635	1728	1726	1727	1729	1722	1726	1715	1666	1689	1739	1751	1746	1750	1757	1768	1773	1660
				1754	1735	1733	1734	1735	1729	1733	1722	1712	1733	1740	1752	1749	1752	1760	1770	1773	1777
				1739	1737	1736	1738	1738	1732	1734	1722	1714	1738	1746	1757	1754	1757	1765	1773	1779	1779
				1743	1737	1738	1738	1738	1733	1735	1724	1714	1742	1749	1758	1757	1761	1768	1776	1781	1781
				1746	1745	1746	1746	1745	1740	1742	1730	1722	1743	1751	1759	1758	1762	1768	1776	1781	1780
				1746	1745	1745	1745	1744	1739	1741	1729	1723	1738	1746	1754	1754	1758	1765	1771	1776	1772
				1753	1742	1743	1741	1742	1737	1738	1725	1721	1749	1757	1759	1756	1765	1771	1776	1783	1778
				1752	1740	1741	1740	1741	1736	1738	1724	1721	1752	1760	1764	1760	1769	1776	1781	1784	1779
				1750	1743	1744	1742	1743	1738	1740	1728	1723	1749	1756	1760	1757	1765	1772	1776	1780	1773
				1746	1743	1745	1742	1742	1737	1738	1728	1722	1747	1752	1757	1754	1762	1768	1773	1776	1769
				1749	1737	1740	1737	1737	1732	1733	1723	1718	1747	1752	1756	1755	1763	1767	1771	1776	1768
				1747	1736	1739	1735	1737	1732	1733	1723	1718	1746	1752	1757	1754	1762	1766	1771	1773	1764
				1740	1740	1742	1738	1738	1733	1734	1727	1720	1750	1755	1760	1759	1767	1770	1774	1775	1767
				1739	1734	1740	1735	1736	1730	1733	1727	1719	1743	1747	1754	1752	1760	1763	1768	1768	1760
				1740	1735	1741	1736	1737	1733	1737	1731	1722	1743	1747	1752	1752	1760	1762	1768	1765	1757
				1737	1727	1733	1728	1729	1724	1729	1727	1714	1737	1741	1746	1746	1753	1754	1760	1759	1750
				1738	1721	1727	1722	1722	1717	1722	1719	1708	1737	1741	1746	1746	1752	1753	1759	1757	1751
				1728	1724	1727	1723	1723	1718	1721	1718	1704	1735	1739	1743	1743	1749	1751	1756	1752	1742
				1719	1718	1722	1718	1718	1712	1716	1714	1706	1729	1733	1738	1738	1743	1743	1749	1745	1738
				1722	1714	1717	1713	1712	1707	1711	1708	1702	1732	1734	1741	1739	1745	1745	1750	1748	1740
				1717	1712	1716	1711	1711	1706	1712	1707	1700	1727	1729	1736	1735	1740	1740	1744	1743	1735
				1713	1708	1711	1708	1706	1702	1708	1704	1696	1725	1727	1734	1733	1737	1738	1741	1738	1729
				1711	1703	1706	1701	1700	1696	1702	1698	1690	1719	1722	1729	1727	1732	1731	1735	1733	1723
				1560	1542	1546	1545	1543	1537	1541	1537	1533	1561	1561	1570	1569	1574	1576	1577	1575	1572
				1557	1549	1554	1551	1549	1544	1549	1545	1541	1561	1561	1570	1568	1573	1575	1576	1574	1573
				1544	1543	1546	1543	1542	1537	1542	1539	1535	1556	1557	1565	1564	1569	1571	1572	1571	1568
				1550	1542	1545	1542	1541	1538	1543	1539	1535	1549	1550	1558	1557	1561	1563	1564	1564	1560
				1543	1533	1536	1533	1533	1530	1534	1530	1525	1547	1549	1557	1555	1560	1561	1562	1562	1559
				1542	1530	1533	1530	1529	1526	1531	1526	1522	1543	1543	1550	1549	1554	1555	1557	1558	1555
				1533	1524	1525	1523	1522	1519	1524	1518	1515	1538	1540	1546	1544	1549	1550	1552	1553	1549
				1530	1519	1521	1518	1518	1515	1521	1514	1511	1533	1535	1541	1539	1544	1546	1547	1549	1545
				1523	1513	1514	1511	1512	1508	1515	1508	1505	1524	1526	1531	1530	1535	1535	1538	1539	1535
				1517	1504	1506	1504	1504	1500	1508	1500	1496	1532	1535	1538	1538	1543	1543	1546	1549	1550
				1376	1495	1496	1495	1495	1491	1499	1489	1487	1505	1509	1519	1513	1518	1517	1522	1524	1395
				899	1440	1511	1511	1514	1509	1517	1507	1506	1519	1519	1530	1524	1530	1527	1531	1463	920
				50 50 50>;

			PS_Config_Lmt_FW_Rawdata_P = <
				2216	2231	2227	2224	2252	2213	2207	2219	65535	65535	2245	2241	2237	2227	2248	2217	2238	2220
				2241	2224	2242	2217	2219	2221	2214	2224	2223	2226	2210	2216	2212	2210	2220	2213	2206	2254
				2223	2214	2217	2213	2235	2242	2227	2228	2214	2240	2227	2206	2234	2240	2205	2224	2228	2238
				2221	2210	2242	2209	2200	2241	2238	2231	2226	2220	2219	2248	2206	2213	2235	2237	2221	2223
				2240	2210	2247	2231	2207	2219	2270	2270	2238	2231	2209	2234	2219	2210	2241	2234	2202	2206
				2242	2254	2219	2192	2235	2224	2213	2224	2207	2210	2219	2237	2203	2185	2214	2237	2242	2227
				2233	2223	2221	2189	2251	2240	2242	2233	2223	2216	2210	2235	2213	2191	2221	2242	2221	2223
				2210	2212	2249	2234	2203	2213	2223	2259	2251	2228	2230	2228	2234	2221	2248	2242	2209	2223
				2252	2230	2212	2231	2221	2207	2217	2221	2234	2223	2212	2227	2216	2210	2231	2230	2227	2231
				2210	2244	2210	2213	2234	2220	2235	2213	2203	2235	2191	2202	2233	2237	2216	2199	2213	2254
				2223	2227	2220	2230	2233	2237	2241	2230	2228	2212	2213	2234	2184	2182	2233	2247	2235	2205
				2210	2226	2199	2213	2245	2221	2234	2228	2210	2248	2228	2231	2233	2235	2230	2224	2227	2233
				2228	2235	2228	2219	2200	2247	2214	2220	2244	2235	2233	2227	2234	2241	2199	2202	2221	2242
				2237	2223	2216	2223	2231	2219	2228	2223	2207	2259	2223	2224	2212	2217	2219	2248	2209	2242
				2240	2214	2213	2240	2241	2240	2235	2213	2227	2251	2226	2235	2220	2216	2230	2228	2221	2230
				2219	2238	2205	2191	2234	2249	2237	2217	2210	2247	2241	2221	2207	2212	2241	2251	2195	2227
				2238	2214	2233	2227	2205	2213	2207	2238	2245	2240	2227	2209	2195	2206	2240	2242	2200	2230
				2210	2234	2233	2240	2206	2216	2212	2221	2233	2226	2238	2224	2230	2233	2200	2209	2241	2212
				2252	2213	2214	2206	2234	2230	2237	2237	2226	2227	2230	2219	2220	2214	2234	2240	2234	2233
				2220	2226	2216	2213	2224	2227	2230	2205	2219	2231	2228	2224	2214	2234	2216	2226	2214	2223
				2258	2199	2235	2242	2217	2220	2220	2219	2213	2224	2221	2216	2230	2223	2224	2207	2217	2238
				2210	2234	2235	2223	2207	2214	2210	2212	2231	2210	2227	2217	2206	2219	2226	2223	2207	2244
				2244	2209	2237	2227	2206	2205	2217	2210	2241	2231	2199	2198	2206	2214	2245	2242	2214	2242
				2223	2224	2216	2206	2252	2242	2213	2185	2217	2258	2261	2254	2249	2221	2202	2209	2258	2207
				2219	2221	2227	2223	2217	2223	2217	2203	2231	2209	2220	2230	2241	2217	2214	2219	2221	2242
				2242	2231	2220	2214	2224	2223	2224	2224	2216	2231	2200	2227	2207	2248	2247	2189	2249	2216
				2234	2209	2202	2217	2241	2224	2213	2221	2221	2209	2212	2217	2216	2226	2235	2230	2231	2203
				2224	2230	2233	2224	2216	2203	2220	2228	2209	2245	2217	2238	2242	2238	2219	2221	2247	2199
				2241	2241	2224	2227	2210	2216	2224	2228	2220	2224	2209	2213	2221	2209	2231	2226	2230	2247
				2217	2210	2220	2241	2235	2242	2237	2200	2199	2230	2212	2210	2209	2238	2235	2223	2251	2223
				2254	2195	2230	2234	2210	2221	2210	2212	2256	2209	2228	2227	2216	2224	2233	2227	2240	2207
				2228	2219	2203	2220	2227	2238	2205	2219	2212	2234	2224	2224	2226	2217	2244	2233	2242	2207
				2231	2212	2237	2231	2224	2221	2210	2217	2230	2205	2207	2220	2202	2226	2219	2209	2219	2221
				2220	2230	2230	2234	2227	2230	2219	2217	2202	2199	2224	2193	2200	2228	2216	2235	2247	2227
				2230	2241	2206	2199	2234	2234	2217	2214	2219	2241	2205	2199	2224	2202	2206	2227	2227	2247
				2223	2231	2219	2214	2212	2216	2223	2226	2221	2240	2235	2221	2206	2193	2209	2192	2228	2206
				1920	1920	1920>;

			PS_Config_Lmt_FW_Rawdata_N = <
				949	956	954	953	965	948	946	951	(-65535)	(-65535)	962	960	958	954	963	950	959	951
				960	953	961	950	951	952	949	953	952	954	947	949	948	947	951	948	945	966
				952	949	950	948	958	961	954	955	949	960	954	945	957	960	945	953	955	959
				952	947	961	946	943	960	959	956	954	951	951	963	945	948	958	958	952	952
				960	947	963	956	946	951	973	973	959	956	946	957	951	947	960	957	943	945
				961	966	951	939	958	953	948	953	946	947	951	958	944	936	949	958	961	954
				957	952	952	938	964	960	961	957	952	949	947	958	948	939	952	961	952	952
				947	948	964	957	944	948	952	968	964	955	955	955	957	952	963	961	946	952
				965	955	948	956	952	946	950	952	957	952	948	954	949	947	956	955	954	956
				947	961	947	948	957	951	958	948	944	958	939	943	957	958	949	942	948	966
				952	954	951	955	957	958	960	955	955	948	948	957	936	935	957	963	958	945
				947	954	942	948	962	952	957	955	947	963	955	956	957	958	955	953	954	957
				955	958	955	951	943	963	949	951	961	958	957	954	957	960	942	943	952	961
				958	952	949	952	956	951	955	952	946	968	952	953	948	950	951	963	946	961
				960	949	948	960	960	960	958	948	954	964	954	958	951	949	955	955	952	955
				951	959	945	939	957	964	958	950	947	963	960	952	946	948	960	964	940	954
				959	949	957	954	945	948	946	959	962	960	954	946	940	945	960	961	943	955
				947	957	957	960	945	949	948	952	957	954	959	953	955	957	943	946	960	948
				965	948	949	945	957	955	958	958	954	954	955	951	951	949	957	960	957	957
				951	954	949	948	953	954	955	945	951	956	955	953	949	957	949	954	949	952
				967	942	958	961	950	951	951	951	948	953	952	949	955	952	953	946	950	959
				947	957	958	952	946	949	947	948	956	947	954	950	945	951	954	952	946	961
				961	946	958	954	945	945	950	947	960	956	942	942	945	949	962	961	949	961
				952	953	949	945	965	961	948	936	950	967	969	966	964	952	943	946	967	946
				951	952	954	952	950	952	950	944	956	946	951	955	960	950	949	951	952	961
				961	956	951	949	953	952	953	953	949	956	943	954	946	963	963	938	964	949
				957	946	943	950	960	953	948	952	952	946	948	950	949	954	958	955	956	944
				953	955	957	953	949	944	951	955	946	962	950	959	961	959	951	952	963	942
				960	960	953	954	947	949	953	955	951	953	946	948	952	946	956	954	955	963
				950	947	951	960	958	961	958	943	942	955	948	947	946	959	958	952	964	952
				966	940	955	957	947	952	947	948	967	946	955	954	949	953	957	954	960	946
				955	951	944	951	954	959	945	951	948	957	953	953	954	950	961	957	961	946
				956	948	958	956	953	952	947	950	955	945	946	951	943	954	951	946	951	952
				951	955	955	957	954	955	951	950	943	942	953	940	943	955	949	958	963	954
				955	960	945	942	957	957	950	949	951	960	945	942	953	943	945	954	954	963
				952	956	951	949	948	949	952	954	952	960	958	952	945	940	946	939	955	945
				240	240	240>;

			PS_Config_Lmt_FW_CC_P = <
				110	124	122	122	121	120	120	120	65535	65535	112	112	110	110	111	112	110	107
				122	112	110	110	109	107	107	107	107	107	110	109	107	107	107	109	110	111
				128	110	107	107	106	105	105	105	105	105	109	107	107	106	107	107	109	111
				116	110	109	109	107	107	106	106	106	107	110	110	109	109	110	110	111	114
				114	110	107	107	107	106	105	105	105	105	109	107	106	106	107	107	109	111
				115	111	110	110	109	107	107	107	107	107	110	109	109	107	109	109	110	112
				114	110	107	107	106	105	105	105	105	107	110	109	107	107	107	109	110	112
				115	110	109	109	107	107	107	106	106	111	111	110	109	109	110	110	110	114
				112	110	109	107	107	106	107	106	105	111	109	107	107	107	107	109	109	111
				115	111	110	110	109	107	109	107	107	112	109	107	107	107	107	107	109	112
				114	109	107	107	106	105	106	105	105	112	107	107	107	107	107	109	109	112
				115	109	107	107	106	106	106	106	105	115	110	110	109	110	110	110	111	115
				112	109	107	107	107	106	106	106	105	112	107	107	107	107	107	109	109	112
				112	110	110	110	109	109	109	110	107	114	109	109	109	109	109	109	110	114
				112	109	107	107	106	106	106	107	105	112	109	109	107	107	109	110	110	112
				115	110	109	109	107	107	107	110	107	114	110	110	109	110	110	110	111	115
				112	110	109	109	107	107	107	109	106	112	107	107	106	106	107	107	109	112
				114	110	110	110	109	109	109	109	107	112	110	109	107	107	109	110	110	114
				112	109	107	107	106	106	106	106	105	112	110	107	107	107	109	109	110	114
				114	110	109	109	107	107	107	107	110	114	110	110	110	110	110	111	111	115
				112	109	107	107	107	107	107	107	107	111	109	107	106	107	107	109	110	114
				112	110	110	110	109	109	110	109	109	112	109	107	107	107	109	109	110	115
				112	107	107	107	106	106	107	107	105	111	109	109	107	109	109	110	110	115
				114	109	109	109	107	107	107	109	106	112	110	110	110	110	111	112	112	117
				111	109	107	107	107	106	107	107	105	109	106	107	107	107	109	109	110	115
				111	110	110	110	110	110	110	110	109	110	109	109	109	110	110	110	112	116
				111	109	109	107	107	107	107	109	106	109	107	107	107	109	110	110	111	115
				114	110	110	110	109	109	110	111	107	110	109	110	110	110	111	112	112	117
				112	110	110	109	107	107	109	110	107	107	107	107	107	107	110	110	111	115
				112	111	111	110	110	110	110	111	109	110	107	109	109	110	110	111	112	117
				112	110	107	107	107	107	107	109	105	109	107	107	107	109	110	110	112	116
				114	110	110	110	109	109	110	110	107	110	109	109	110	110	111	112	114	119
				111	110	110	109	107	107	110	110	106	107	107	106	107	107	109	110	112	116
				112	111	111	110	110	110	112	111	109	117	119	117	119	120	120	121	124	132
				111	110	109	109	107	107	110	109	106	106	110	111	107	107	109	109	110	111
				110	121	120	120	120	120	122	122	122	120	120	121	117	117	117	117	119	116
				314 314 314>;

			PS_Config_Lmt_FW_CC_N = <
				67	76	75	75	74	73	73	73	(-65535)	(-65535)	69	69	67	67	68	69	67	66
				75	69	67	67	66	66	66	66	66	66	67	66	66	66	66	66	67	68
				79	67	66	66	65	64	64	64	64	64	66	66	66	65	66	66	66	68
				71	67	66	66	66	66	65	65	65	66	67	67	66	66	67	67	68	69
				69	67	66	66	66	65	64	64	64	64	66	66	65	65	66	66	66	68
				70	68	67	67	66	66	66	66	66	66	67	66	66	66	66	66	67	69
				69	67	66	66	65	64	64	64	64	66	67	66	66	66	66	66	67	69
				70	67	66	66	66	66	66	65	65	68	68	67	66	66	67	67	67	69
				69	67	66	66	66	65	66	65	64	68	66	66	66	66	66	66	66	68
				70	68	67	67	66	66	66	66	66	69	66	66	66	66	66	66	66	69
				69	66	66	66	65	64	65	64	64	69	66	66	66	66	66	66	66	69
				70	66	66	66	65	65	65	65	64	70	67	67	66	67	67	67	68	70
				69	66	66	66	66	65	65	65	64	69	66	66	66	66	66	66	66	69
				69	67	67	67	66	66	66	67	66	69	66	66	66	66	66	66	67	69
				69	66	66	66	65	65	65	66	64	69	66	66	66	66	66	67	67	69
				70	67	66	66	66	66	66	67	66	69	67	67	66	67	67	67	68	70
				69	67	66	66	66	66	66	66	65	69	66	66	65	65	66	66	66	69
				69	67	67	67	66	66	66	66	66	69	67	66	66	66	66	67	67	69
				69	66	66	66	65	65	65	65	64	69	67	66	66	66	66	66	67	69
				69	67	66	66	66	66	66	66	67	69	67	67	67	67	67	68	68	70
				69	66	66	66	66	66	66	66	66	68	66	66	65	66	66	66	67	69
				69	67	67	67	66	66	67	66	66	69	66	66	66	66	66	66	67	70
				69	66	66	66	65	65	66	66	64	68	66	66	66	66	66	67	67	70
				69	66	66	66	66	66	66	66	65	69	67	67	67	67	68	69	69	72
				68	66	66	66	66	65	66	66	64	66	65	66	66	66	66	66	67	70
				68	67	67	67	67	67	67	67	66	67	66	66	66	67	67	67	69	71
				68	66	66	66	66	66	66	66	65	66	66	66	66	66	67	67	68	70
				69	67	67	67	66	66	67	68	66	67	66	67	67	67	68	69	69	72
				69	67	67	66	66	66	66	67	66	66	66	66	66	66	67	67	68	70
				69	68	68	67	67	67	67	68	66	67	66	66	66	67	67	68	69	72
				69	67	66	66	66	66	66	66	64	66	66	66	66	66	67	67	69	71
				69	67	67	67	66	66	67	67	66	67	66	66	67	67	68	69	69	72
				68	67	67	66	66	66	67	67	65	66	66	65	66	66	66	67	69	71
				69	68	68	67	67	67	69	68	66	72	72	72	72	73	73	74	76	81
				68	67	66	66	66	66	67	66	65	65	67	68	66	66	66	66	67	68
				67	74	73	73	73	73	75	75	75	73	73	74	72	72	72	72	72	71
				30	30	30>;

			PS_Config_Lmt_FW_Diff_P = <
				50	50	50	50	50	50	50	50	65535	65535	50	50	50	50	50	50	50	50
				50	50	50	50	50	50	50	50	50	50	50	50	50	50	50	50	50	50
				50	50	50	50	50	50	50	50	50	50	50	50	50	50	50	50	50	50
				50	50	50	50	50	50	50	50	50	50	50	50	50	50	50	50	50	50
				50	50	50	50	50	50	50	50	50	50	50	50	50	50	50	50	50	50
				50	50	50	50	50	50	50	50	50	50	50	50	50	50	50	50	50	50
				50	50	50	50	50	50	50	50	50	50	50	50	50	50	50	50	50	50
				50	50	50	50	50	50	50	50	50	50	50	50	50	50	50	50	50	50
				50	50	50	50	50	50	50	50	50	50	50	50	50	50	50	50	50	50
				50	50	50	50	50	50	50	50	50	50	50	50	50	50	50	50	50	50
				50	50	50	50	50	50	50	50	50	50	50	50	50	50	50	50	50	50
				50	50	50	50	50	50	50	50	50	50	50	50	50	50	50	50	50	50
				50	50	50	50	50	50	50	50	50	50	50	50	50	50	50	50	50	50
				50	50	50	50	50	50	50	50	50	50	50	50	50	50	50	50	50	50
				50	50	50	50	50	50	50	50	50	50	50	50	50	50	50	50	50	50
				50	50	50	50	50	50	50	50	50	50	50	50	50	50	50	50	50	50
				50	50	50	50	50	50	50	50	50	50	50	50	50	50	50	50	50	50
				50	50	50	50	50	50	50	50	50	50	50	50	50	50	50	50	50	50
				50	50	50	50	50	50	50	50	50	50	50	50	50	50	50	50	50	50
				50	50	50	50	50	50	50	50	50	50	50	50	50	50	50	50	50	50
				50	50	50	50	50	50	50	50	50	50	50	50	50	50	50	50	50	50
				50	50	50	50	50	50	50	50	50	50	50	50	50	50	50	50	50	50
				50	50	50	50	50	50	50	50	50	50	50	50	50	50	50	50	50	50
				50	50	50	50	50	50	50	50	50	50	50	50	50	50	50	50	50	50
				50	50	50	50	50	50	50	50	50	50	50	50	50	50	50	50	50	50
				50	50	50	50	50	50	50	50	50	50	50	50	50	50	50	50	50	50
				50	50	50	50	50	50	50	50	50	50	50	50	50	50	50	50	50	50
				50	50	50	50	50	50	50	50	50	50	50	50	50	50	50	50	50	50
				50	50	50	50	50	50	50	50	50	50	50	50	50	50	50	50	50	50
				50	50	50	50	50	50	50	50	50	50	50	50	50	50	50	50	50	50
				50	50	50	50	50	50	50	50	50	50	50	50	50	50	50	50	50	50
				50	50	50	50	50	50	50	50	50	50	50	50	50	50	50	50	50	50
				50	50	50	50	50	50	50	50	50	50	50	50	50	50	50	50	50	50
				50	50	50	50	50	50	50	50	50	50	50	50	50	50	50	50	50	50
				50	50	50	50	50	50	50	50	50	50	50	50	50	50	50	50	50	50
				50	50	50	50	50	50	50	50	50	50	50	50	50	50	50	50	50	50
				75	75	75>;

			PS_Config_Lmt_FW_Diff_N = <
				(-50)	(-50)	(-50)	(-50)	(-50)	(-50)	(-50)	(-50)	(-65535)	(-65535)	(-50)	(-50)	(-50)	(-50)	(-50)	(-50)	(-50)	(-50)
				(-50)	(-50)	(-50)	(-50)	(-50)	(-50)	(-50)	(-50)	(-50)	(-50)	(-50)	(-50)	(-50)	(-50)	(-50)	(-50)	(-50)	(-50)
				(-50)	(-50)	(-50)	(-50)	(-50)	(-50)	(-50)	(-50)	(-50)	(-50)	(-50)	(-50)	(-50)	(-50)	(-50)	(-50)	(-50)	(-50)
				(-50)	(-50)	(-50)	(-50)	(-50)	(-50)	(-50)	(-50)	(-50)	(-50)	(-50)	(-50)	(-50)	(-50)	(-50)	(-50)	(-50)	(-50)
				(-50)	(-50)	(-50)	(-50)	(-50)	(-50)	(-50)	(-50)	(-50)	(-50)	(-50)	(-50)	(-50)	(-50)	(-50)	(-50)	(-50)	(-50)
				(-50)	(-50)	(-50)	(-50)	(-50)	(-50)	(-50)	(-50)	(-50)	(-50)	(-50)	(-50)	(-50)	(-50)	(-50)	(-50)	(-50)	(-50)
				(-50)	(-50)	(-50)	(-50)	(-50)	(-50)	(-50)	(-50)	(-50)	(-50)	(-50)	(-50)	(-50)	(-50)	(-50)	(-50)	(-50)	(-50)
				(-50)	(-50)	(-50)	(-50)	(-50)	(-50)	(-50)	(-50)	(-50)	(-50)	(-50)	(-50)	(-50)	(-50)	(-50)	(-50)	(-50)	(-50)
				(-50)	(-50)	(-50)	(-50)	(-50)	(-50)	(-50)	(-50)	(-50)	(-50)	(-50)	(-50)	(-50)	(-50)	(-50)	(-50)	(-50)	(-50)
				(-50)	(-50)	(-50)	(-50)	(-50)	(-50)	(-50)	(-50)	(-50)	(-50)	(-50)	(-50)	(-50)	(-50)	(-50)	(-50)	(-50)	(-50)
				(-50)	(-50)	(-50)	(-50)	(-50)	(-50)	(-50)	(-50)	(-50)	(-50)	(-50)	(-50)	(-50)	(-50)	(-50)	(-50)	(-50)	(-50)
				(-50)	(-50)	(-50)	(-50)	(-50)	(-50)	(-50)	(-50)	(-50)	(-50)	(-50)	(-50)	(-50)	(-50)	(-50)	(-50)	(-50)	(-50)
				(-50)	(-50)	(-50)	(-50)	(-50)	(-50)	(-50)	(-50)	(-50)	(-50)	(-50)	(-50)	(-50)	(-50)	(-50)	(-50)	(-50)	(-50)
				(-50)	(-50)	(-50)	(-50)	(-50)	(-50)	(-50)	(-50)	(-50)	(-50)	(-50)	(-50)	(-50)	(-50)	(-50)	(-50)	(-50)	(-50)
				(-50)	(-50)	(-50)	(-50)	(-50)	(-50)	(-50)	(-50)	(-50)	(-50)	(-50)	(-50)	(-50)	(-50)	(-50)	(-50)	(-50)	(-50)
				(-50)	(-50)	(-50)	(-50)	(-50)	(-50)	(-50)	(-50)	(-50)	(-50)	(-50)	(-50)	(-50)	(-50)	(-50)	(-50)	(-50)	(-50)
				(-50)	(-50)	(-50)	(-50)	(-50)	(-50)	(-50)	(-50)	(-50)	(-50)	(-50)	(-50)	(-50)	(-50)	(-50)	(-50)	(-50)	(-50)
				(-50)	(-50)	(-50)	(-50)	(-50)	(-50)	(-50)	(-50)	(-50)	(-50)	(-50)	(-50)	(-50)	(-50)	(-50)	(-50)	(-50)	(-50)
				(-50)	(-50)	(-50)	(-50)	(-50)	(-50)	(-50)	(-50)	(-50)	(-50)	(-50)	(-50)	(-50)	(-50)	(-50)	(-50)	(-50)	(-50)
				(-50)	(-50)	(-50)	(-50)	(-50)	(-50)	(-50)	(-50)	(-50)	(-50)	(-50)	(-50)	(-50)	(-50)	(-50)	(-50)	(-50)	(-50)
				(-50)	(-50)	(-50)	(-50)	(-50)	(-50)	(-50)	(-50)	(-50)	(-50)	(-50)	(-50)	(-50)	(-50)	(-50)	(-50)	(-50)	(-50)
				(-50)	(-50)	(-50)	(-50)	(-50)	(-50)	(-50)	(-50)	(-50)	(-50)	(-50)	(-50)	(-50)	(-50)	(-50)	(-50)	(-50)	(-50)
				(-50)	(-50)	(-50)	(-50)	(-50)	(-50)	(-50)	(-50)	(-50)	(-50)	(-50)	(-50)	(-50)	(-50)	(-50)	(-50)	(-50)	(-50)
				(-50)	(-50)	(-50)	(-50)	(-50)	(-50)	(-50)	(-50)	(-50)	(-50)	(-50)	(-50)	(-50)	(-50)	(-50)	(-50)	(-50)	(-50)
				(-50)	(-50)	(-50)	(-50)	(-50)	(-50)	(-50)	(-50)	(-50)	(-50)	(-50)	(-50)	(-50)	(-50)	(-50)	(-50)	(-50)	(-50)
				(-50)	(-50)	(-50)	(-50)	(-50)	(-50)	(-50)	(-50)	(-50)	(-50)	(-50)	(-50)	(-50)	(-50)	(-50)	(-50)	(-50)	(-50)
				(-50)	(-50)	(-50)	(-50)	(-50)	(-50)	(-50)	(-50)	(-50)	(-50)	(-50)	(-50)	(-50)	(-50)	(-50)	(-50)	(-50)	(-50)
				(-50)	(-50)	(-50)	(-50)	(-50)	(-50)	(-50)	(-50)	(-50)	(-50)	(-50)	(-50)	(-50)	(-50)	(-50)	(-50)	(-50)	(-50)
				(-50)	(-50)	(-50)	(-50)	(-50)	(-50)	(-50)	(-50)	(-50)	(-50)	(-50)	(-50)	(-50)	(-50)	(-50)	(-50)	(-50)	(-50)
				(-50)	(-50)	(-50)	(-50)	(-50)	(-50)	(-50)	(-50)	(-50)	(-50)	(-50)	(-50)	(-50)	(-50)	(-50)	(-50)	(-50)	(-50)
				(-50)	(-50)	(-50)	(-50)	(-50)	(-50)	(-50)	(-50)	(-50)	(-50)	(-50)	(-50)	(-50)	(-50)	(-50)	(-50)	(-50)	(-50)
				(-50)	(-50)	(-50)	(-50)	(-50)	(-50)	(-50)	(-50)	(-50)	(-50)	(-50)	(-50)	(-50)	(-50)	(-50)	(-50)	(-50)	(-50)
				(-50)	(-50)	(-50)	(-50)	(-50)	(-50)	(-50)	(-50)	(-50)	(-50)	(-50)	(-50)	(-50)	(-50)	(-50)	(-50)	(-50)	(-50)
				(-50)	(-50)	(-50)	(-50)	(-50)	(-50)	(-50)	(-50)	(-50)	(-50)	(-50)	(-50)	(-50)	(-50)	(-50)	(-50)	(-50)	(-50)
				(-50)	(-50)	(-50)	(-50)	(-50)	(-50)	(-50)	(-50)	(-50)	(-50)	(-50)	(-50)	(-50)	(-50)	(-50)	(-50)	(-50)	(-50)
				(-50)	(-50)	(-50)	(-50)	(-50)	(-50)	(-50)	(-50)	(-50)	(-50)	(-50)	(-50)	(-50)	(-50)	(-50)	(-50)	(-50)	(-50)
				(-75)	(-75)	(-75)>;

			PS_Config_Diff_Test_Frame = <50>;
		};/*}}}*/

	};

};
